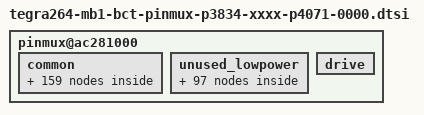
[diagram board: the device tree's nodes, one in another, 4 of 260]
/*This dtsi file was generated by T264_Pinmux_Config_CVM_Jedha_P4070.xlsm Revision: 9 */
/*
 * SPDX-FileCopyrightText: Copyright (c) 2024-2025 NVIDIA CORPORATION & AFFILIATES. All rights reserved.
 * SPDX-License-Identifier: BSD-3-Clause
 *
 * Redistribution and use in source and binary forms, with or without
 * modification, are permitted provided that the following conditions are met:
 *
 * 1. Redistributions of source code must retain the above copyright notice, this
 * list of conditions and the following disclaimer.
 *
 * 2. Redistributions in binary form must reproduce the above copyright notice,
 * this list of conditions and the following disclaimer in the documentation
 * and/or other materials provided with the distribution.
 * 
 * 3. Neither the name of the copyright holder nor the names of its
 * contributors may be used to endorse or promote products derived from
 * this software without specific prior written permission.
 *
 * THIS SOFTWARE IS PROVIDED BY THE COPYRIGHT HOLDERS AND CONTRIBUTORS 'AS IS'
 * AND ANY EXPRESS OR IMPLIED WARRANTIES, INCLUDING, BUT NOT LIMITED TO, THE
 * IMPLIED WARRANTIES OF MERCHANTABILITY AND FITNESS FOR A PARTICULAR PURPOSE ARE
 * DISCLAIMED. IN NO EVENT SHALL THE COPYRIGHT HOLDER OR CONTRIBUTORS BE LIABLE
 * FOR ANY DIRECT, INDIRECT, INCIDENTAL, SPECIAL, EXEMPLARY, OR CONSEQUENTIAL
 * DAMAGES (INCLUDING, BUT NOT LIMITED TO, PROCUREMENT OF SUBSTITUTE GOODS OR
 * SERVICES; LOSS OF USE, DATA, OR PROFITS; OR BUSINESS INTERRUPTION) HOWEVER
 * CAUSED AND ON ANY THEORY OF LIABILITY, WHETHER IN CONTRACT, STRICT LIABILITY,
 * OR TORT (INCLUDING NEGLIGENCE OR OTHERWISE) ARISING IN ANY WAY OUT OF THE USE
 * OF THIS SOFTWARE, EVEN IF ADVISED OF THE POSSIBILITY OF SUCH DAMAGE.
 */


#include "t264-pinctrl-tegra.h"

#include "./tegra264-mb1-bct-gpio-p3834-xxxx-p4071-0000.dtsi"

pinmux@ac281000 {
		common {
			/* SFIO Pin Configuration */
			shutdown_n {
				nvidia,pins = "shutdown_n";
				nvidia,function = "shutdown_n";
				nvidia,pull = <TEGRA_PIN_PULL_NONE>;
				nvidia,tristate = <TEGRA_PIN_DISABLE>;
				nvidia,enable-input = <TEGRA_PIN_DISABLE>;
				nvidia,drv-type = <TEGRA_PIN_1X_DRIVER>;
				nvidia,e-io-od = <TEGRA_PIN_ENABLE>;
				nvidia,e-lpbk = <TEGRA_PIN_DISABLE>;
			};

			batt_oc_paa3 {
				nvidia,pins = "batt_oc_paa3";
				nvidia,function = "soc_therm_oc2";
				nvidia,pull = <TEGRA_PIN_PULL_UP>;
				nvidia,tristate = <TEGRA_PIN_ENABLE>;
				nvidia,enable-input = <TEGRA_PIN_ENABLE>;
				nvidia,drv-type = <TEGRA_PIN_1X_DRIVER>;
				nvidia,e-io-od = <TEGRA_PIN_DISABLE>;
				nvidia,e-lpbk = <TEGRA_PIN_DISABLE>;
			};

			hdmi_cec_paa6 {
				nvidia,pins = "hdmi_cec_paa6";
				nvidia,function = "hdmi_cec";
				nvidia,pull = <TEGRA_PIN_PULL_NONE>;
				nvidia,tristate = <TEGRA_PIN_DISABLE>;
				nvidia,enable-input = <TEGRA_PIN_ENABLE>;
				nvidia,drv-type = <TEGRA_PIN_1X_DRIVER>;
				nvidia,e-io-od = <TEGRA_PIN_ENABLE>;
				nvidia,e-lpbk = <TEGRA_PIN_DISABLE>;
			};

			gen2_i2c_scl_pcc0 {
				nvidia,pins = "gen2_i2c_scl_pcc0";
				nvidia,function = "i2c2_clk";
				nvidia,pull = <TEGRA_PIN_PULL_NONE>;
				nvidia,tristate = <TEGRA_PIN_DISABLE>;
				nvidia,enable-input = <TEGRA_PIN_ENABLE>;
				nvidia,drv-type = <TEGRA_PIN_1X_DRIVER>;
				nvidia,e-io-od = <TEGRA_PIN_ENABLE>;
				nvidia,e-lpbk = <TEGRA_PIN_DISABLE>;
			};

			gen2_i2c_sda_pcc1 {
				nvidia,pins = "gen2_i2c_sda_pcc1";
				nvidia,function = "i2c2_dat";
				nvidia,pull = <TEGRA_PIN_PULL_NONE>;
				nvidia,tristate = <TEGRA_PIN_DISABLE>;
				nvidia,enable-input = <TEGRA_PIN_ENABLE>;
				nvidia,drv-type = <TEGRA_PIN_1X_DRIVER>;
				nvidia,e-io-od = <TEGRA_PIN_ENABLE>;
				nvidia,e-lpbk = <TEGRA_PIN_DISABLE>;
			};

			gen3_i2c_scl_pcc2 {
				nvidia,pins = "gen3_i2c_scl_pcc2";
				nvidia,function = "i2c3_clk";
				nvidia,pull = <TEGRA_PIN_PULL_NONE>;
				nvidia,tristate = <TEGRA_PIN_DISABLE>;
				nvidia,enable-input = <TEGRA_PIN_ENABLE>;
				nvidia,drv-type = <TEGRA_PIN_1X_DRIVER>;
				nvidia,e-io-od = <TEGRA_PIN_ENABLE>;
				nvidia,e-lpbk = <TEGRA_PIN_DISABLE>;
			};

			gen3_i2c_sda_pcc3 {
				nvidia,pins = "gen3_i2c_sda_pcc3";
				nvidia,function = "i2c3_dat";
				nvidia,pull = <TEGRA_PIN_PULL_NONE>;
				nvidia,tristate = <TEGRA_PIN_DISABLE>;
				nvidia,enable-input = <TEGRA_PIN_ENABLE>;
				nvidia,drv-type = <TEGRA_PIN_1X_DRIVER>;
				nvidia,e-io-od = <TEGRA_PIN_ENABLE>;
				nvidia,e-lpbk = <TEGRA_PIN_DISABLE>;
			};

			gp_pwm4_pcc4 {
				nvidia,pins = "gp_pwm4_pcc4";
				nvidia,function = "gp_pwm4";
				nvidia,pull = <TEGRA_PIN_PULL_NONE>;
				nvidia,tristate = <TEGRA_PIN_DISABLE>;
				nvidia,enable-input = <TEGRA_PIN_DISABLE>;
				nvidia,drv-type = <TEGRA_PIN_1X_DRIVER>;
				nvidia,e-io-od = <TEGRA_PIN_DISABLE>;
				nvidia,e-lpbk = <TEGRA_PIN_DISABLE>;
			};

			uart0_tx_pcc5 {
				nvidia,pins = "uart0_tx_pcc5";
				nvidia,function = "uarta_txd";
				nvidia,pull = <TEGRA_PIN_PULL_NONE>;
				nvidia,tristate = <TEGRA_PIN_DISABLE>;
				nvidia,enable-input = <TEGRA_PIN_DISABLE>;
				nvidia,drv-type = <TEGRA_PIN_1X_DRIVER>;
				nvidia,e-io-od = <TEGRA_PIN_DISABLE>;
				nvidia,e-lpbk = <TEGRA_PIN_DISABLE>;
			};

			uart0_rx_pcc6 {
				nvidia,pins = "uart0_rx_pcc6";
				nvidia,function = "uarta_rxd";
				nvidia,pull = <TEGRA_PIN_PULL_NONE>;
				nvidia,tristate = <TEGRA_PIN_ENABLE>;
				nvidia,enable-input = <TEGRA_PIN_ENABLE>;
				nvidia,drv-type = <TEGRA_PIN_1X_DRIVER>;
				nvidia,e-io-od = <TEGRA_PIN_DISABLE>;
				nvidia,e-lpbk = <TEGRA_PIN_DISABLE>;
			};

			soc_gpio23_pdd5 {
				nvidia,pins = "soc_gpio23_pdd5";
				nvidia,function = "tsc_edge_out2";
				nvidia,pull = <TEGRA_PIN_PULL_NONE>;
				nvidia,tristate = <TEGRA_PIN_DISABLE>;
				nvidia,enable-input = <TEGRA_PIN_DISABLE>;
				nvidia,drv-type = <TEGRA_PIN_1X_DRIVER>;
				nvidia,e-io-od = <TEGRA_PIN_DISABLE>;
				nvidia,e-lpbk = <TEGRA_PIN_DISABLE>;
			};

			soc_gpio25_pdd7 {
				nvidia,pins = "soc_gpio25_pdd7";
				nvidia,function = "tsc_edge_out0";
				nvidia,pull = <TEGRA_PIN_PULL_NONE>;
				nvidia,tristate = <TEGRA_PIN_DISABLE>;
				nvidia,enable-input = <TEGRA_PIN_DISABLE>;
				nvidia,drv-type = <TEGRA_PIN_1X_DRIVER>;
				nvidia,e-io-od = <TEGRA_PIN_DISABLE>;
				nvidia,e-lpbk = <TEGRA_PIN_DISABLE>;
			};

			soc_gpio26_pee0 {
				nvidia,pins = "soc_gpio26_pee0";
				nvidia,function = "tsc_edge_out1";
				nvidia,pull = <TEGRA_PIN_PULL_NONE>;
				nvidia,tristate = <TEGRA_PIN_DISABLE>;
				nvidia,enable-input = <TEGRA_PIN_DISABLE>;
				nvidia,drv-type = <TEGRA_PIN_1X_DRIVER>;
				nvidia,e-io-od = <TEGRA_PIN_DISABLE>;
				nvidia,e-lpbk = <TEGRA_PIN_DISABLE>;
			};

			soc_gpio28_pee2 {
				nvidia,pins = "soc_gpio28_pee2";
				nvidia,function = "l0l1_rst_out_n";
				nvidia,pull = <TEGRA_PIN_PULL_UP>;
				nvidia,tristate = <TEGRA_PIN_DISABLE>;
				nvidia,enable-input = <TEGRA_PIN_DISABLE>;
				nvidia,drv-type = <TEGRA_PIN_1X_DRIVER>;
				nvidia,e-io-od = <TEGRA_PIN_DISABLE>;
				nvidia,e-lpbk = <TEGRA_PIN_DISABLE>;
			};

			soc_gpio29_pee3 {
				nvidia,pins = "soc_gpio29_pee3";
				nvidia,function = "l2_rst_out_n";
				nvidia,pull = <TEGRA_PIN_PULL_UP>;
				nvidia,tristate = <TEGRA_PIN_DISABLE>;
				nvidia,enable-input = <TEGRA_PIN_DISABLE>;
				nvidia,drv-type = <TEGRA_PIN_1X_DRIVER>;
				nvidia,e-io-od = <TEGRA_PIN_DISABLE>;
				nvidia,e-lpbk = <TEGRA_PIN_DISABLE>;
			};

			qspi2_sck {
				nvidia,pins = "qspi2_sck";
				nvidia,function = "qspi2_sck";
				nvidia,pull = <TEGRA_PIN_PULL_DOWN>;
				nvidia,tristate = <TEGRA_PIN_DISABLE>;
				nvidia,enable-input = <TEGRA_PIN_ENABLE>;
				nvidia,drv-type = <TEGRA_PIN_2X_DRIVER>;
				nvidia,e-io-od = <TEGRA_PIN_DISABLE>;
				nvidia,e-lpbk = <TEGRA_PIN_ENABLE>;
			};

			qspi2_cs0 {
				nvidia,pins = "qspi2_cs0";
				nvidia,function = "qspi2_cs0";
				nvidia,pull = <TEGRA_PIN_PULL_UP>;
				nvidia,tristate = <TEGRA_PIN_DISABLE>;
				nvidia,enable-input = <TEGRA_PIN_DISABLE>;
				nvidia,drv-type = <TEGRA_PIN_2X_DRIVER>;
				nvidia,e-io-od = <TEGRA_PIN_DISABLE>;
				nvidia,e-lpbk = <TEGRA_PIN_DISABLE>;
			};

			qspi2_d0 {
				nvidia,pins = "qspi2_d0";
				nvidia,function = "qspi2_io0";
				nvidia,pull = <TEGRA_PIN_PULL_UP>;
				nvidia,tristate = <TEGRA_PIN_DISABLE>;
				nvidia,enable-input = <TEGRA_PIN_ENABLE>;
				nvidia,drv-type = <TEGRA_PIN_2X_DRIVER>;
				nvidia,e-io-od = <TEGRA_PIN_DISABLE>;
				nvidia,e-lpbk = <TEGRA_PIN_DISABLE>;
			};

			qspi2_d1 {
				nvidia,pins = "qspi2_d1";
				nvidia,function = "qspi2_io1";
				nvidia,pull = <TEGRA_PIN_PULL_UP>;
				nvidia,tristate = <TEGRA_PIN_DISABLE>;
				nvidia,enable-input = <TEGRA_PIN_ENABLE>;
				nvidia,drv-type = <TEGRA_PIN_2X_DRIVER>;
				nvidia,e-io-od = <TEGRA_PIN_DISABLE>;
				nvidia,e-lpbk = <TEGRA_PIN_DISABLE>;
			};

			pwm1_pa0 {
				nvidia,pins = "pwm1_pa0";
				nvidia,function = "gp_pwm1";
				nvidia,pull = <TEGRA_PIN_PULL_NONE>;
				nvidia,tristate = <TEGRA_PIN_ENABLE>;
				nvidia,enable-input = <TEGRA_PIN_DISABLE>;
				nvidia,drv-type = <TEGRA_PIN_1X_DRIVER>;
				nvidia,e-io-od = <TEGRA_PIN_DISABLE>;
				nvidia,e-lpbk = <TEGRA_PIN_DISABLE>;
			};

			pwm6_pa1 {
				nvidia,pins = "pwm6_pa1";
				nvidia,function = "gp_pwm6";
				nvidia,pull = <TEGRA_PIN_PULL_NONE>;
				nvidia,tristate = <TEGRA_PIN_ENABLE>;
				nvidia,enable-input = <TEGRA_PIN_DISABLE>;
				nvidia,drv-type = <TEGRA_PIN_1X_DRIVER>;
				nvidia,e-io-od = <TEGRA_PIN_DISABLE>;
				nvidia,e-lpbk = <TEGRA_PIN_DISABLE>;
			};

			pwm7_pa2 {
				nvidia,pins = "pwm7_pa2";
				nvidia,function = "gp_pwm7";
				nvidia,pull = <TEGRA_PIN_PULL_NONE>;
				nvidia,tristate = <TEGRA_PIN_ENABLE>;
				nvidia,enable-input = <TEGRA_PIN_DISABLE>;
				nvidia,drv-type = <TEGRA_PIN_1X_DRIVER>;
				nvidia,e-io-od = <TEGRA_PIN_DISABLE>;
				nvidia,e-lpbk = <TEGRA_PIN_DISABLE>;
			};

			pwm8_pa3 {
				nvidia,pins = "pwm8_pa3";
				nvidia,function = "gp_pwm8";
				nvidia,pull = <TEGRA_PIN_PULL_NONE>;
				nvidia,tristate = <TEGRA_PIN_ENABLE>;
				nvidia,enable-input = <TEGRA_PIN_DISABLE>;
				nvidia,drv-type = <TEGRA_PIN_1X_DRIVER>;
				nvidia,e-io-od = <TEGRA_PIN_DISABLE>;
				nvidia,e-lpbk = <TEGRA_PIN_DISABLE>;
			};

			ufs0_ref_clk_pa4 {
				nvidia,pins = "ufs0_ref_clk_pa4";
				nvidia,function = "ufs0";
				nvidia,pull = <TEGRA_PIN_PULL_NONE>;
				nvidia,tristate = <TEGRA_PIN_DISABLE>;
				nvidia,enable-input = <TEGRA_PIN_DISABLE>;
				nvidia,drv-type = <TEGRA_PIN_2X_DRIVER>;
				nvidia,e-io-od = <TEGRA_PIN_DISABLE>;
				nvidia,e-lpbk = <TEGRA_PIN_DISABLE>;
			};

			ufs0_rst_n_pa5 {
				nvidia,pins = "ufs0_rst_n_pa5";
				nvidia,function = "ufs0";
				nvidia,pull = <TEGRA_PIN_PULL_NONE>;
				nvidia,tristate = <TEGRA_PIN_DISABLE>;
				nvidia,enable-input = <TEGRA_PIN_DISABLE>;
				nvidia,drv-type = <TEGRA_PIN_2X_DRIVER>;
				nvidia,e-io-od = <TEGRA_PIN_DISABLE>;
				nvidia,e-lpbk = <TEGRA_PIN_DISABLE>;
			};

			pex_l1_clkreq_n_pb0 {
				nvidia,pins = "pex_l1_clkreq_n_pb0";
				nvidia,function = "pe1_clkreq_l";
				nvidia,pull = <TEGRA_PIN_PULL_NONE>;
				nvidia,tristate = <TEGRA_PIN_DISABLE>;
				nvidia,enable-input = <TEGRA_PIN_ENABLE>;
				nvidia,drv-type = <TEGRA_PIN_1X_DRIVER>;
				nvidia,e-io-od = <TEGRA_PIN_ENABLE>;
				nvidia,e-lpbk = <TEGRA_PIN_DISABLE>;
			};

			pex_l1_rst_n_pb1 {
				nvidia,pins = "pex_l1_rst_n_pb1";
				nvidia,function = "pe1_rst_l";
				nvidia,pull = <TEGRA_PIN_PULL_NONE>;
				nvidia,tristate = <TEGRA_PIN_DISABLE>;
				nvidia,enable-input = <TEGRA_PIN_DISABLE>;
				nvidia,drv-type = <TEGRA_PIN_1X_DRIVER>;
				nvidia,e-io-od = <TEGRA_PIN_ENABLE>;
				nvidia,e-lpbk = <TEGRA_PIN_DISABLE>;
			};

			pex_l2_clkreq_n_pb2 {
				nvidia,pins = "pex_l2_clkreq_n_pb2";
				nvidia,function = "pe2_clkreq_l";
				nvidia,pull = <TEGRA_PIN_PULL_NONE>;
				nvidia,tristate = <TEGRA_PIN_DISABLE>;
				nvidia,enable-input = <TEGRA_PIN_ENABLE>;
				nvidia,drv-type = <TEGRA_PIN_1X_DRIVER>;
				nvidia,e-io-od = <TEGRA_PIN_ENABLE>;
				nvidia,e-lpbk = <TEGRA_PIN_DISABLE>;
			};

			pex_l2_rst_n_pb3 {
				nvidia,pins = "pex_l2_rst_n_pb3";
				nvidia,function = "pe2_rst_l";
				nvidia,pull = <TEGRA_PIN_PULL_NONE>;
				nvidia,tristate = <TEGRA_PIN_DISABLE>;
				nvidia,enable-input = <TEGRA_PIN_DISABLE>;
				nvidia,drv-type = <TEGRA_PIN_1X_DRIVER>;
				nvidia,e-io-od = <TEGRA_PIN_ENABLE>;
				nvidia,e-lpbk = <TEGRA_PIN_DISABLE>;
			};

			pex_l3_clkreq_n_pb4 {
				nvidia,pins = "pex_l3_clkreq_n_pb4";
				nvidia,function = "pe3_clkreq_l";
				nvidia,pull = <TEGRA_PIN_PULL_NONE>;
				nvidia,tristate = <TEGRA_PIN_DISABLE>;
				nvidia,enable-input = <TEGRA_PIN_ENABLE>;
				nvidia,drv-type = <TEGRA_PIN_1X_DRIVER>;
				nvidia,e-io-od = <TEGRA_PIN_ENABLE>;
				nvidia,e-lpbk = <TEGRA_PIN_DISABLE>;
			};

			pex_l3_rst_n_pb5 {
				nvidia,pins = "pex_l3_rst_n_pb5";
				nvidia,function = "pe3_rst_l";
				nvidia,pull = <TEGRA_PIN_PULL_NONE>;
				nvidia,tristate = <TEGRA_PIN_DISABLE>;
				nvidia,enable-input = <TEGRA_PIN_DISABLE>;
				nvidia,drv-type = <TEGRA_PIN_1X_DRIVER>;
				nvidia,e-io-od = <TEGRA_PIN_ENABLE>;
				nvidia,e-lpbk = <TEGRA_PIN_DISABLE>;
			};

			pex_l5_clkreq_n_pd2 {
				nvidia,pins = "pex_l5_clkreq_n_pd2";
				nvidia,function = "pe5_clkreq_l";
				nvidia,pull = <TEGRA_PIN_PULL_NONE>;
				nvidia,tristate = <TEGRA_PIN_DISABLE>;
				nvidia,enable-input = <TEGRA_PIN_ENABLE>;
				nvidia,drv-type = <TEGRA_PIN_1X_DRIVER>;
				nvidia,e-io-od = <TEGRA_PIN_DISABLE>;
				nvidia,e-lpbk = <TEGRA_PIN_DISABLE>;
			};

			pex_l5_rst_n_pd3 {
				nvidia,pins = "pex_l5_rst_n_pd3";
				nvidia,function = "pe5_rst_l";
				nvidia,pull = <TEGRA_PIN_PULL_NONE>;
				nvidia,tristate = <TEGRA_PIN_DISABLE>;
				nvidia,enable-input = <TEGRA_PIN_DISABLE>;
				nvidia,drv-type = <TEGRA_PIN_1X_DRIVER>;
				nvidia,e-io-od = <TEGRA_PIN_DISABLE>;
				nvidia,e-lpbk = <TEGRA_PIN_DISABLE>;
			};

			can0_dout_pab0 {
				nvidia,pins = "can0_dout_pab0";
				nvidia,function = "can0_dout";
				nvidia,pull = <TEGRA_PIN_PULL_NONE>;
				nvidia,tristate = <TEGRA_PIN_DISABLE>;
				nvidia,enable-input = <TEGRA_PIN_DISABLE>;
				nvidia,drv-type = <TEGRA_PIN_DEFAULT_DRIVE_1X>;
				nvidia,e-lpbk = <TEGRA_PIN_DISABLE>;
			};

			can0_din_pab1 {
				nvidia,pins = "can0_din_pab1";
				nvidia,function = "can0_din";
				nvidia,pull = <TEGRA_PIN_PULL_NONE>;
				nvidia,tristate = <TEGRA_PIN_ENABLE>;
				nvidia,enable-input = <TEGRA_PIN_ENABLE>;
				nvidia,drv-type = <TEGRA_PIN_DEFAULT_DRIVE_1X>;
				nvidia,e-lpbk = <TEGRA_PIN_DISABLE>;
			};

			can1_dout_pac0 {
				nvidia,pins = "can1_dout_pac0";
				nvidia,function = "can1_dout";
				nvidia,pull = <TEGRA_PIN_PULL_NONE>;
				nvidia,tristate = <TEGRA_PIN_DISABLE>;
				nvidia,enable-input = <TEGRA_PIN_DISABLE>;
				nvidia,drv-type = <TEGRA_PIN_DEFAULT_DRIVE_1X>;
				nvidia,e-lpbk = <TEGRA_PIN_DISABLE>;
			};

			can1_din_pac1 {
				nvidia,pins = "can1_din_pac1";
				nvidia,function = "can1_din";
				nvidia,pull = <TEGRA_PIN_PULL_NONE>;
				nvidia,tristate = <TEGRA_PIN_ENABLE>;
				nvidia,enable-input = <TEGRA_PIN_ENABLE>;
				nvidia,drv-type = <TEGRA_PIN_DEFAULT_DRIVE_1X>;
				nvidia,e-lpbk = <TEGRA_PIN_DISABLE>;
			};

			can2_dout_pad0 {
				nvidia,pins = "can2_dout_pad0";
				nvidia,function = "can2_dout";
				nvidia,pull = <TEGRA_PIN_PULL_NONE>;
				nvidia,tristate = <TEGRA_PIN_DISABLE>;
				nvidia,enable-input = <TEGRA_PIN_DISABLE>;
				nvidia,drv-type = <TEGRA_PIN_DEFAULT_DRIVE_1X>;
				nvidia,e-lpbk = <TEGRA_PIN_DISABLE>;
			};

			can2_din_pad1 {
				nvidia,pins = "can2_din_pad1";
				nvidia,function = "can2_din";
				nvidia,pull = <TEGRA_PIN_PULL_NONE>;
				nvidia,tristate = <TEGRA_PIN_ENABLE>;
				nvidia,enable-input = <TEGRA_PIN_ENABLE>;
				nvidia,drv-type = <TEGRA_PIN_DEFAULT_DRIVE_1X>;
				nvidia,e-lpbk = <TEGRA_PIN_DISABLE>;
			};

			can3_dout_pae0 {
				nvidia,pins = "can3_dout_pae0";
				nvidia,function = "can3_dout";
				nvidia,pull = <TEGRA_PIN_PULL_NONE>;
				nvidia,tristate = <TEGRA_PIN_DISABLE>;
				nvidia,enable-input = <TEGRA_PIN_DISABLE>;
				nvidia,drv-type = <TEGRA_PIN_DEFAULT_DRIVE_1X>;
				nvidia,e-lpbk = <TEGRA_PIN_DISABLE>;
			};

			can3_din_pae1 {
				nvidia,pins = "can3_din_pae1";
				nvidia,function = "can3_din";
				nvidia,pull = <TEGRA_PIN_PULL_NONE>;
				nvidia,tristate = <TEGRA_PIN_ENABLE>;
				nvidia,enable-input = <TEGRA_PIN_ENABLE>;
				nvidia,drv-type = <TEGRA_PIN_DEFAULT_DRIVE_1X>;
				nvidia,e-lpbk = <TEGRA_PIN_DISABLE>;
			};

			dp_aux_ch0_hpd_pf3 {
				nvidia,pins = "dp_aux_ch0_hpd_pf3";
				nvidia,function = "dp_aux_ch0_hpd";
				nvidia,pull = <TEGRA_PIN_PULL_NONE>;
				nvidia,tristate = <TEGRA_PIN_ENABLE>;
				nvidia,enable-input = <TEGRA_PIN_ENABLE>;
				nvidia,drv-type = <TEGRA_PIN_1X_DRIVER>;
				nvidia,e-io-od = <TEGRA_PIN_DISABLE>;
				nvidia,e-lpbk = <TEGRA_PIN_DISABLE>;
			};

			dp_aux_ch2_hpd_pf5 {
				nvidia,pins = "dp_aux_ch2_hpd_pf5";
				nvidia,function = "dp_aux_ch2_hpd";
				nvidia,pull = <TEGRA_PIN_PULL_NONE>;
				nvidia,tristate = <TEGRA_PIN_ENABLE>;
				nvidia,enable-input = <TEGRA_PIN_ENABLE>;
				nvidia,drv-type = <TEGRA_PIN_1X_DRIVER>;
				nvidia,e-io-od = <TEGRA_PIN_DISABLE>;
				nvidia,e-lpbk = <TEGRA_PIN_DISABLE>;
			};

			dp_aux_ch3_hpd_pf6 {
				nvidia,pins = "dp_aux_ch3_hpd_pf6";
				nvidia,function = "dp_aux_ch3_hpd";
				nvidia,pull = <TEGRA_PIN_PULL_NONE>;
				nvidia,tristate = <TEGRA_PIN_ENABLE>;
				nvidia,enable-input = <TEGRA_PIN_ENABLE>;
				nvidia,drv-type = <TEGRA_PIN_1X_DRIVER>;
				nvidia,e-io-od = <TEGRA_PIN_DISABLE>;
				nvidia,e-lpbk = <TEGRA_PIN_DISABLE>;
			};

			pwm2_pf7 {
				nvidia,pins = "pwm2_pf7";
				nvidia,function = "gp_pwm2";
				nvidia,pull = <TEGRA_PIN_PULL_NONE>;
				nvidia,tristate = <TEGRA_PIN_DISABLE>;
				nvidia,enable-input = <TEGRA_PIN_DISABLE>;
				nvidia,drv-type = <TEGRA_PIN_1X_DRIVER>;
				nvidia,e-io-od = <TEGRA_PIN_DISABLE>;
				nvidia,e-lpbk = <TEGRA_PIN_DISABLE>;
			};

			pwm3_pg0 {
				nvidia,pins = "pwm3_pg0";
				nvidia,function = "gp_pwm3";
				nvidia,pull = <TEGRA_PIN_PULL_NONE>;
				nvidia,tristate = <TEGRA_PIN_DISABLE>;
				nvidia,enable-input = <TEGRA_PIN_DISABLE>;
				nvidia,drv-type = <TEGRA_PIN_1X_DRIVER>;
				nvidia,e-io-od = <TEGRA_PIN_DISABLE>;
				nvidia,e-lpbk = <TEGRA_PIN_DISABLE>;
			};

			gen7_i2c_scl_pg1 {
				nvidia,pins = "gen7_i2c_scl_pg1";
				nvidia,function = "i2c7_clk";
				nvidia,pull = <TEGRA_PIN_PULL_NONE>;
				nvidia,tristate = <TEGRA_PIN_DISABLE>;
				nvidia,enable-input = <TEGRA_PIN_ENABLE>;
				nvidia,drv-type = <TEGRA_PIN_1X_DRIVER>;
				nvidia,e-io-od = <TEGRA_PIN_ENABLE>;
				nvidia,e-lpbk = <TEGRA_PIN_DISABLE>;
			};

			gen7_i2c_sda_pg2 {
				nvidia,pins = "gen7_i2c_sda_pg2";
				nvidia,function = "i2c7_dat";
				nvidia,pull = <TEGRA_PIN_PULL_NONE>;
				nvidia,tristate = <TEGRA_PIN_DISABLE>;
				nvidia,enable-input = <TEGRA_PIN_ENABLE>;
				nvidia,drv-type = <TEGRA_PIN_1X_DRIVER>;
				nvidia,e-io-od = <TEGRA_PIN_ENABLE>;
				nvidia,e-lpbk = <TEGRA_PIN_DISABLE>;
			};

			gen9_i2c_scl_pg3 {
				nvidia,pins = "gen9_i2c_scl_pg3";
				nvidia,function = "i2c9_clk";
				nvidia,pull = <TEGRA_PIN_PULL_NONE>;
				nvidia,tristate = <TEGRA_PIN_DISABLE>;
				nvidia,enable-input = <TEGRA_PIN_ENABLE>;
				nvidia,drv-type = <TEGRA_PIN_1X_DRIVER>;
				nvidia,e-io-od = <TEGRA_PIN_ENABLE>;
				nvidia,e-lpbk = <TEGRA_PIN_DISABLE>;
			};

			gen9_i2c_sda_pg4 {
				nvidia,pins = "gen9_i2c_sda_pg4";
				nvidia,function = "i2c9_dat";
				nvidia,pull = <TEGRA_PIN_PULL_NONE>;
				nvidia,tristate = <TEGRA_PIN_DISABLE>;
				nvidia,enable-input = <TEGRA_PIN_ENABLE>;
				nvidia,drv-type = <TEGRA_PIN_1X_DRIVER>;
				nvidia,e-io-od = <TEGRA_PIN_ENABLE>;
				nvidia,e-lpbk = <TEGRA_PIN_DISABLE>;
			};

			dp_aux_ch0_p {
				nvidia,pins = "dp_aux_ch0_p";
				nvidia,function = "dp_aux_ch0_p";
				nvidia,pull = <TEGRA_PIN_PULL_NONE>;
				nvidia,tristate = <TEGRA_PIN_DISABLE>;
				nvidia,enable-input = <TEGRA_PIN_ENABLE>;
				nvidia,drv-type = <TEGRA_PIN_1X_DRIVER>;
				nvidia,e-io-od = <TEGRA_PIN_DISABLE>;
				nvidia,e-lpbk = <TEGRA_PIN_DISABLE>;
			};

			dp_aux_ch0_n {
				nvidia,pins = "dp_aux_ch0_n";
				nvidia,function = "dp_aux_ch0_n";
				nvidia,pull = <TEGRA_PIN_PULL_NONE>;
				nvidia,tristate = <TEGRA_PIN_DISABLE>;
				nvidia,enable-input = <TEGRA_PIN_ENABLE>;
				nvidia,drv-type = <TEGRA_PIN_1X_DRIVER>;
				nvidia,e-io-od = <TEGRA_PIN_DISABLE>;
				nvidia,e-lpbk = <TEGRA_PIN_DISABLE>;
			};

			dp_aux_ch1_p {
				nvidia,pins = "dp_aux_ch1_p";
				nvidia,function = "i2c10_clk";
				nvidia,pull = <TEGRA_PIN_PULL_NONE>;
				nvidia,tristate = <TEGRA_PIN_DISABLE>;
				nvidia,enable-input = <TEGRA_PIN_ENABLE>;
				nvidia,drv-type = <TEGRA_PIN_1X_DRIVER>;
				nvidia,e-io-od = <TEGRA_PIN_ENABLE>;
				nvidia,e-lpbk = <TEGRA_PIN_DISABLE>;
			};

			dp_aux_ch1_n {
				nvidia,pins = "dp_aux_ch1_n";
				nvidia,function = "i2c10_dat";
				nvidia,pull = <TEGRA_PIN_PULL_NONE>;
				nvidia,tristate = <TEGRA_PIN_DISABLE>;
				nvidia,enable-input = <TEGRA_PIN_ENABLE>;
				nvidia,drv-type = <TEGRA_PIN_1X_DRIVER>;
				nvidia,e-io-od = <TEGRA_PIN_ENABLE>;
				nvidia,e-lpbk = <TEGRA_PIN_DISABLE>;
			};

			dp_aux_ch2_p {
				nvidia,pins = "dp_aux_ch2_p";
				nvidia,function = "dp_aux_ch2_p";
				nvidia,pull = <TEGRA_PIN_PULL_NONE>;
				nvidia,tristate = <TEGRA_PIN_DISABLE>;
				nvidia,enable-input = <TEGRA_PIN_ENABLE>;
				nvidia,drv-type = <TEGRA_PIN_1X_DRIVER>;
				nvidia,e-io-od = <TEGRA_PIN_DISABLE>;
				nvidia,e-lpbk = <TEGRA_PIN_DISABLE>;
			};

			dp_aux_ch2_n {
				nvidia,pins = "dp_aux_ch2_n";
				nvidia,function = "dp_aux_ch2_n";
				nvidia,pull = <TEGRA_PIN_PULL_NONE>;
				nvidia,tristate = <TEGRA_PIN_DISABLE>;
				nvidia,enable-input = <TEGRA_PIN_ENABLE>;
				nvidia,drv-type = <TEGRA_PIN_1X_DRIVER>;
				nvidia,e-io-od = <TEGRA_PIN_DISABLE>;
				nvidia,e-lpbk = <TEGRA_PIN_DISABLE>;
			};

			dp_aux_ch3_p {
				nvidia,pins = "dp_aux_ch3_p";
				nvidia,function = "dp_aux_ch3_p";
				nvidia,pull = <TEGRA_PIN_PULL_NONE>;
				nvidia,tristate = <TEGRA_PIN_DISABLE>;
				nvidia,enable-input = <TEGRA_PIN_ENABLE>;
				nvidia,drv-type = <TEGRA_PIN_1X_DRIVER>;
				nvidia,e-io-od = <TEGRA_PIN_DISABLE>;
				nvidia,e-lpbk = <TEGRA_PIN_DISABLE>;
			};

			dp_aux_ch3_n {
				nvidia,pins = "dp_aux_ch3_n";
				nvidia,function = "dp_aux_ch3_n";
				nvidia,pull = <TEGRA_PIN_PULL_NONE>;
				nvidia,tristate = <TEGRA_PIN_DISABLE>;
				nvidia,enable-input = <TEGRA_PIN_ENABLE>;
				nvidia,drv-type = <TEGRA_PIN_1X_DRIVER>;
				nvidia,e-io-od = <TEGRA_PIN_DISABLE>;
				nvidia,e-lpbk = <TEGRA_PIN_DISABLE>;
			};

			uart10_tx_ph2 {
				nvidia,pins = "uart10_tx_ph2";
				nvidia,function = "uartk_txd";
				nvidia,pull = <TEGRA_PIN_PULL_NONE>;
				nvidia,tristate = <TEGRA_PIN_DISABLE>;
				nvidia,enable-input = <TEGRA_PIN_DISABLE>;
				nvidia,drv-type = <TEGRA_PIN_1X_DRIVER>;
				nvidia,e-io-od = <TEGRA_PIN_DISABLE>;
				nvidia,e-lpbk = <TEGRA_PIN_DISABLE>;
			};

			uart10_rx_ph3 {
				nvidia,pins = "uart10_rx_ph3";
				nvidia,function = "uartk_rxd";
				nvidia,pull = <TEGRA_PIN_PULL_NONE>;
				nvidia,tristate = <TEGRA_PIN_ENABLE>;
				nvidia,enable-input = <TEGRA_PIN_ENABLE>;
				nvidia,drv-type = <TEGRA_PIN_1X_DRIVER>;
				nvidia,e-io-od = <TEGRA_PIN_DISABLE>;
				nvidia,e-lpbk = <TEGRA_PIN_DISABLE>;
			};

			spi3_sck_ph6 {
				nvidia,pins = "spi3_sck_ph6";
				nvidia,function = "spi3_sck";
				nvidia,pull = <TEGRA_PIN_PULL_NONE>;
				nvidia,tristate = <TEGRA_PIN_DISABLE>;
				nvidia,enable-input = <TEGRA_PIN_ENABLE>;
				nvidia,drv-type = <TEGRA_PIN_1X_DRIVER>;
				nvidia,e-io-od = <TEGRA_PIN_DISABLE>;
				nvidia,e-lpbk = <TEGRA_PIN_DISABLE>;
			};

			spi3_miso_ph7 {
				nvidia,pins = "spi3_miso_ph7";
				nvidia,function = "spi3_din";
				nvidia,pull = <TEGRA_PIN_PULL_UP>;
				nvidia,tristate = <TEGRA_PIN_DISABLE>;
				nvidia,enable-input = <TEGRA_PIN_ENABLE>;
				nvidia,drv-type = <TEGRA_PIN_1X_DRIVER>;
				nvidia,e-io-od = <TEGRA_PIN_DISABLE>;
				nvidia,e-lpbk = <TEGRA_PIN_DISABLE>;
			};

			spi3_mosi_pj0 {
				nvidia,pins = "spi3_mosi_pj0";
				nvidia,function = "spi3_dout";
				nvidia,pull = <TEGRA_PIN_PULL_NONE>;
				nvidia,tristate = <TEGRA_PIN_DISABLE>;
				nvidia,enable-input = <TEGRA_PIN_ENABLE>;
				nvidia,drv-type = <TEGRA_PIN_1X_DRIVER>;
				nvidia,e-io-od = <TEGRA_PIN_DISABLE>;
				nvidia,e-lpbk = <TEGRA_PIN_DISABLE>;
			};

			spi3_cs0_pj1 {
				nvidia,pins = "spi3_cs0_pj1";
				nvidia,function = "spi3_cs0";
				nvidia,pull = <TEGRA_PIN_PULL_NONE>;
				nvidia,tristate = <TEGRA_PIN_DISABLE>;
				nvidia,enable-input = <TEGRA_PIN_ENABLE>;
				nvidia,drv-type = <TEGRA_PIN_1X_DRIVER>;
				nvidia,e-io-od = <TEGRA_PIN_DISABLE>;
				nvidia,e-lpbk = <TEGRA_PIN_DISABLE>;
			};

			uart5_tx_pj3 {
				nvidia,pins = "uart5_tx_pj3";
				nvidia,function = "uartf_txd";
				nvidia,pull = <TEGRA_PIN_PULL_NONE>;
				nvidia,tristate = <TEGRA_PIN_DISABLE>;
				nvidia,enable-input = <TEGRA_PIN_DISABLE>;
				nvidia,drv-type = <TEGRA_PIN_1X_DRIVER>;
				nvidia,e-io-od = <TEGRA_PIN_DISABLE>;
				nvidia,e-lpbk = <TEGRA_PIN_DISABLE>;
			};

			uart5_rx_pj4 {
				nvidia,pins = "uart5_rx_pj4";
				nvidia,function = "uartf_rxd";
				nvidia,pull = <TEGRA_PIN_PULL_UP>;
				nvidia,tristate = <TEGRA_PIN_ENABLE>;
				nvidia,enable-input = <TEGRA_PIN_ENABLE>;
				nvidia,drv-type = <TEGRA_PIN_1X_DRIVER>;
				nvidia,e-io-od = <TEGRA_PIN_DISABLE>;
				nvidia,e-lpbk = <TEGRA_PIN_DISABLE>;
			};

			uart5_rts_n_pj5 {
				nvidia,pins = "uart5_rts_n_pj5";
				nvidia,function = "uartf_rts";
				nvidia,pull = <TEGRA_PIN_PULL_NONE>;
				nvidia,tristate = <TEGRA_PIN_DISABLE>;
				nvidia,enable-input = <TEGRA_PIN_DISABLE>;
				nvidia,drv-type = <TEGRA_PIN_1X_DRIVER>;
				nvidia,e-io-od = <TEGRA_PIN_DISABLE>;
				nvidia,e-lpbk = <TEGRA_PIN_DISABLE>;
			};

			uart5_cts_n_pj6 {
				nvidia,pins = "uart5_cts_n_pj6";
				nvidia,function = "uartf_cts";
				nvidia,pull = <TEGRA_PIN_PULL_UP>;
				nvidia,tristate = <TEGRA_PIN_ENABLE>;
				nvidia,enable-input = <TEGRA_PIN_ENABLE>;
				nvidia,drv-type = <TEGRA_PIN_1X_DRIVER>;
				nvidia,e-io-od = <TEGRA_PIN_DISABLE>;
				nvidia,e-lpbk = <TEGRA_PIN_DISABLE>;
			};

			extperiph1_clk_pk4 {
				nvidia,pins = "extperiph1_clk_pk4";
				nvidia,function = "extperiph1_clk";
				nvidia,pull = <TEGRA_PIN_PULL_NONE>;
				nvidia,tristate = <TEGRA_PIN_DISABLE>;
				nvidia,enable-input = <TEGRA_PIN_DISABLE>;
				nvidia,drv-type = <TEGRA_PIN_1X_DRIVER>;
				nvidia,e-io-od = <TEGRA_PIN_DISABLE>;
				nvidia,e-lpbk = <TEGRA_PIN_DISABLE>;
			};

			extperiph2_clk_pk5 {
				nvidia,pins = "extperiph2_clk_pk5";
				nvidia,function = "extperiph2_clk";
				nvidia,pull = <TEGRA_PIN_PULL_NONE>;
				nvidia,tristate = <TEGRA_PIN_DISABLE>;
				nvidia,enable-input = <TEGRA_PIN_DISABLE>;
				nvidia,drv-type = <TEGRA_PIN_1X_DRIVER>;
				nvidia,e-io-od = <TEGRA_PIN_DISABLE>;
				nvidia,e-lpbk = <TEGRA_PIN_DISABLE>;
			};

			gen12_i2c_scl_pk6 {
				nvidia,pins = "gen12_i2c_scl_pk6";
				nvidia,function = "i2c12_clk";
				nvidia,pull = <TEGRA_PIN_PULL_NONE>;
				nvidia,tristate = <TEGRA_PIN_DISABLE>;
				nvidia,enable-input = <TEGRA_PIN_ENABLE>;
				nvidia,drv-type = <TEGRA_PIN_1X_DRIVER>;
				nvidia,e-io-od = <TEGRA_PIN_ENABLE>;
				nvidia,e-lpbk = <TEGRA_PIN_DISABLE>;
			};

			gen12_i2c_sda_pk7 {
				nvidia,pins = "gen12_i2c_sda_pk7";
				nvidia,function = "i2c12_dat";
				nvidia,pull = <TEGRA_PIN_PULL_NONE>;
				nvidia,tristate = <TEGRA_PIN_DISABLE>;
				nvidia,enable-input = <TEGRA_PIN_ENABLE>;
				nvidia,drv-type = <TEGRA_PIN_1X_DRIVER>;
				nvidia,e-io-od = <TEGRA_PIN_ENABLE>;
				nvidia,e-lpbk = <TEGRA_PIN_DISABLE>;
			};

			soc_gpio124_pl0 {
				nvidia,pins = "soc_gpio124_pl0";
				nvidia,function = "soc_therm_oc3";
				nvidia,pull = <TEGRA_PIN_PULL_UP>;
				nvidia,tristate = <TEGRA_PIN_ENABLE>;
				nvidia,enable-input = <TEGRA_PIN_ENABLE>;
				nvidia,drv-type = <TEGRA_PIN_1X_DRIVER>;
				nvidia,e-io-od = <TEGRA_PIN_DISABLE>;
				nvidia,e-lpbk = <TEGRA_PIN_DISABLE>;
			};

			fan_tach0_pl2 {
				nvidia,pins = "fan_tach0_pl2";
				nvidia,function = "nv_therm_fan_tach0";
				nvidia,pull = <TEGRA_PIN_PULL_UP>;
				nvidia,tristate = <TEGRA_PIN_ENABLE>;
				nvidia,enable-input = <TEGRA_PIN_ENABLE>;
				nvidia,drv-type = <TEGRA_PIN_1X_DRIVER>;
				nvidia,e-io-od = <TEGRA_PIN_DISABLE>;
				nvidia,e-lpbk = <TEGRA_PIN_DISABLE>;
			};

			soc_gpio129_pl5 {
				nvidia,pins = "soc_gpio129_pl5";
				nvidia,function = "extperiph3_clk";
				nvidia,pull = <TEGRA_PIN_PULL_NONE>;
				nvidia,tristate = <TEGRA_PIN_DISABLE>;
				nvidia,enable-input = <TEGRA_PIN_DISABLE>;
				nvidia,drv-type = <TEGRA_PIN_1X_DRIVER>;
				nvidia,e-io-od = <TEGRA_PIN_DISABLE>;
				nvidia,e-lpbk = <TEGRA_PIN_DISABLE>;
			};

			soc_gpio130_pl6 {
				nvidia,pins = "soc_gpio130_pl6";
				nvidia,function = "extperiph4_clk";
				nvidia,pull = <TEGRA_PIN_PULL_NONE>;
				nvidia,tristate = <TEGRA_PIN_DISABLE>;
				nvidia,enable-input = <TEGRA_PIN_DISABLE>;
				nvidia,drv-type = <TEGRA_PIN_1X_DRIVER>;
				nvidia,e-io-od = <TEGRA_PIN_DISABLE>;
				nvidia,e-lpbk = <TEGRA_PIN_DISABLE>;
			};

			uart9_tx_pm2 {
				nvidia,pins = "uart9_tx_pm2";
				nvidia,function = "uartj_txd";
				nvidia,pull = <TEGRA_PIN_PULL_NONE>;
				nvidia,tristate = <TEGRA_PIN_DISABLE>;
				nvidia,enable-input = <TEGRA_PIN_DISABLE>;
				nvidia,drv-type = <TEGRA_PIN_1X_DRIVER>;
				nvidia,e-io-od = <TEGRA_PIN_DISABLE>;
				nvidia,e-lpbk = <TEGRA_PIN_DISABLE>;
			};

			uart9_rx_pm3 {
				nvidia,pins = "uart9_rx_pm3";
				nvidia,function = "uartj_rxd";
				nvidia,pull = <TEGRA_PIN_PULL_UP>;
				nvidia,tristate = <TEGRA_PIN_ENABLE>;
				nvidia,enable-input = <TEGRA_PIN_ENABLE>;
				nvidia,drv-type = <TEGRA_PIN_1X_DRIVER>;
				nvidia,e-io-od = <TEGRA_PIN_DISABLE>;
				nvidia,e-lpbk = <TEGRA_PIN_DISABLE>;
			};

			uart9_rts_n_pm4 {
				nvidia,pins = "uart9_rts_n_pm4";
				nvidia,function = "uartj_rts";
				nvidia,pull = <TEGRA_PIN_PULL_NONE>;
				nvidia,tristate = <TEGRA_PIN_DISABLE>;
				nvidia,enable-input = <TEGRA_PIN_DISABLE>;
				nvidia,drv-type = <TEGRA_PIN_1X_DRIVER>;
				nvidia,e-io-od = <TEGRA_PIN_DISABLE>;
				nvidia,e-lpbk = <TEGRA_PIN_DISABLE>;
			};

			uart9_cts_n_pm5 {
				nvidia,pins = "uart9_cts_n_pm5";
				nvidia,function = "uartj_cts";
				nvidia,pull = <TEGRA_PIN_PULL_UP>;
				nvidia,tristate = <TEGRA_PIN_ENABLE>;
				nvidia,enable-input = <TEGRA_PIN_ENABLE>;
				nvidia,drv-type = <TEGRA_PIN_1X_DRIVER>;
				nvidia,e-io-od = <TEGRA_PIN_DISABLE>;
				nvidia,e-lpbk = <TEGRA_PIN_DISABLE>;
			};

			dap4_sclk_pp6 {
				nvidia,pins = "dap4_sclk_pp6";
				nvidia,function = "i2s4_sclk";
				nvidia,pull = <TEGRA_PIN_PULL_NONE>;
				nvidia,tristate = <TEGRA_PIN_DISABLE>;
				nvidia,enable-input = <TEGRA_PIN_ENABLE>;
				nvidia,drv-type = <TEGRA_PIN_1X_DRIVER>;
				nvidia,e-io-od = <TEGRA_PIN_DISABLE>;
				nvidia,e-lpbk = <TEGRA_PIN_DISABLE>;
			};

			dap4_dout_pp7 {
				nvidia,pins = "dap4_dout_pp7";
				nvidia,function = "i2s4_sdata_out";
				nvidia,pull = <TEGRA_PIN_PULL_NONE>;
				nvidia,tristate = <TEGRA_PIN_DISABLE>;
				nvidia,enable-input = <TEGRA_PIN_DISABLE>;
				nvidia,drv-type = <TEGRA_PIN_1X_DRIVER>;
				nvidia,e-io-od = <TEGRA_PIN_DISABLE>;
				nvidia,e-lpbk = <TEGRA_PIN_DISABLE>;
			};

			dap4_din_pq0 {
				nvidia,pins = "dap4_din_pq0";
				nvidia,function = "i2s4_sdata_in";
				nvidia,pull = <TEGRA_PIN_PULL_NONE>;
				nvidia,tristate = <TEGRA_PIN_ENABLE>;
				nvidia,enable-input = <TEGRA_PIN_ENABLE>;
				nvidia,drv-type = <TEGRA_PIN_1X_DRIVER>;
				nvidia,e-io-od = <TEGRA_PIN_DISABLE>;
				nvidia,e-lpbk = <TEGRA_PIN_DISABLE>;
			};

			dap4_fs_pq1 {
				nvidia,pins = "dap4_fs_pq1";
				nvidia,function = "i2s4_lrck";
				nvidia,pull = <TEGRA_PIN_PULL_NONE>;
				nvidia,tristate = <TEGRA_PIN_DISABLE>;
				nvidia,enable-input = <TEGRA_PIN_ENABLE>;
				nvidia,drv-type = <TEGRA_PIN_1X_DRIVER>;
				nvidia,e-io-od = <TEGRA_PIN_DISABLE>;
				nvidia,e-lpbk = <TEGRA_PIN_DISABLE>;
			};

			aud_mclk_pr0 {
				nvidia,pins = "aud_mclk_pr0";
				nvidia,function = "aud_mclk";
				nvidia,pull = <TEGRA_PIN_PULL_NONE>;
				nvidia,tristate = <TEGRA_PIN_DISABLE>;
				nvidia,enable-input = <TEGRA_PIN_DISABLE>;
				nvidia,drv-type = <TEGRA_PIN_1X_DRIVER>;
				nvidia,e-io-od = <TEGRA_PIN_DISABLE>;
				nvidia,e-lpbk = <TEGRA_PIN_DISABLE>;
			};

			dap1_sclk_pr2 {
				nvidia,pins = "dap1_sclk_pr2";
				nvidia,function = "i2s1_sclk";
				nvidia,pull = <TEGRA_PIN_PULL_NONE>;
				nvidia,tristate = <TEGRA_PIN_DISABLE>;
				nvidia,enable-input = <TEGRA_PIN_ENABLE>;
				nvidia,drv-type = <TEGRA_PIN_1X_DRIVER>;
				nvidia,e-io-od = <TEGRA_PIN_DISABLE>;
				nvidia,e-lpbk = <TEGRA_PIN_DISABLE>;
			};

			dap1_out_pr3 {
				nvidia,pins = "dap1_out_pr3";
				nvidia,function = "i2s1_sdata_out";
				nvidia,pull = <TEGRA_PIN_PULL_NONE>;
				nvidia,tristate = <TEGRA_PIN_DISABLE>;
				nvidia,enable-input = <TEGRA_PIN_DISABLE>;
				nvidia,drv-type = <TEGRA_PIN_1X_DRIVER>;
				nvidia,e-io-od = <TEGRA_PIN_DISABLE>;
				nvidia,e-lpbk = <TEGRA_PIN_DISABLE>;
			};

			dap1_in_pr4 {
				nvidia,pins = "dap1_in_pr4";
				nvidia,function = "i2s1_sdata_in";
				nvidia,pull = <TEGRA_PIN_PULL_NONE>;
				nvidia,tristate = <TEGRA_PIN_ENABLE>;
				nvidia,enable-input = <TEGRA_PIN_ENABLE>;
				nvidia,drv-type = <TEGRA_PIN_1X_DRIVER>;
				nvidia,e-io-od = <TEGRA_PIN_DISABLE>;
				nvidia,e-lpbk = <TEGRA_PIN_DISABLE>;
			};

			dap1_fs_pr5 {
				nvidia,pins = "dap1_fs_pr5";
				nvidia,function = "i2s1_lrck";
				nvidia,pull = <TEGRA_PIN_PULL_NONE>;
				nvidia,tristate = <TEGRA_PIN_DISABLE>;
				nvidia,enable-input = <TEGRA_PIN_ENABLE>;
				nvidia,drv-type = <TEGRA_PIN_1X_DRIVER>;
				nvidia,e-io-od = <TEGRA_PIN_DISABLE>;
				nvidia,e-lpbk = <TEGRA_PIN_DISABLE>;
			};

			qspi0_sck_pt0 {
				nvidia,pins = "qspi0_sck_pt0";
				nvidia,function = "qspi0_sck";
				nvidia,pull = <TEGRA_PIN_PULL_DOWN>;
				nvidia,tristate = <TEGRA_PIN_DISABLE>;
				nvidia,enable-input = <TEGRA_PIN_ENABLE>;
				nvidia,drv-type = <TEGRA_PIN_2X_DRIVER>;
				nvidia,e-io-od = <TEGRA_PIN_DISABLE>;
				nvidia,e-lpbk = <TEGRA_PIN_ENABLE>;
			};

			qspi0_cs_n_pt1 {
				nvidia,pins = "qspi0_cs_n_pt1";
				nvidia,function = "qspi0_cs_n";
				nvidia,pull = <TEGRA_PIN_PULL_UP>;
				nvidia,tristate = <TEGRA_PIN_DISABLE>;
				nvidia,enable-input = <TEGRA_PIN_DISABLE>;
				nvidia,drv-type = <TEGRA_PIN_2X_DRIVER>;
				nvidia,e-io-od = <TEGRA_PIN_DISABLE>;
				nvidia,e-lpbk = <TEGRA_PIN_DISABLE>;
			};

			qspi0_io0_pt2 {
				nvidia,pins = "qspi0_io0_pt2";
				nvidia,function = "qspi0_io0";
				nvidia,pull = <TEGRA_PIN_PULL_UP>;
				nvidia,tristate = <TEGRA_PIN_DISABLE>;
				nvidia,enable-input = <TEGRA_PIN_ENABLE>;
				nvidia,drv-type = <TEGRA_PIN_2X_DRIVER>;
				nvidia,e-io-od = <TEGRA_PIN_DISABLE>;
				nvidia,e-lpbk = <TEGRA_PIN_DISABLE>;
			};

			qspi0_io1_pt3 {
				nvidia,pins = "qspi0_io1_pt3";
				nvidia,function = "qspi0_io1";
				nvidia,pull = <TEGRA_PIN_PULL_UP>;
				nvidia,tristate = <TEGRA_PIN_DISABLE>;
				nvidia,enable-input = <TEGRA_PIN_ENABLE>;
				nvidia,drv-type = <TEGRA_PIN_2X_DRIVER>;
				nvidia,e-io-od = <TEGRA_PIN_DISABLE>;
				nvidia,e-lpbk = <TEGRA_PIN_DISABLE>;
			};

			qspi0_io2_pt4 {
				nvidia,pins = "qspi0_io2_pt4";
				nvidia,function = "qspi0_io2";
				nvidia,pull = <TEGRA_PIN_PULL_UP>;
				nvidia,tristate = <TEGRA_PIN_DISABLE>;
				nvidia,enable-input = <TEGRA_PIN_ENABLE>;
				nvidia,drv-type = <TEGRA_PIN_2X_DRIVER>;
				nvidia,e-io-od = <TEGRA_PIN_DISABLE>;
				nvidia,e-lpbk = <TEGRA_PIN_DISABLE>;
			};

			qspi0_io3_pt5 {
				nvidia,pins = "qspi0_io3_pt5";
				nvidia,function = "qspi0_io3";
				nvidia,pull = <TEGRA_PIN_PULL_UP>;
				nvidia,tristate = <TEGRA_PIN_DISABLE>;
				nvidia,enable-input = <TEGRA_PIN_ENABLE>;
				nvidia,drv-type = <TEGRA_PIN_2X_DRIVER>;
				nvidia,e-io-od = <TEGRA_PIN_DISABLE>;
				nvidia,e-lpbk = <TEGRA_PIN_DISABLE>;
			};

			gen1_i2c_scl_pw2 {
				nvidia,pins = "gen1_i2c_scl_pw2";
				nvidia,function = "i2c1_clk";
				nvidia,pull = <TEGRA_PIN_PULL_NONE>;
				nvidia,tristate = <TEGRA_PIN_DISABLE>;
				nvidia,enable-input = <TEGRA_PIN_ENABLE>;
				nvidia,drv-type = <TEGRA_PIN_1X_DRIVER>;
				nvidia,e-io-od = <TEGRA_PIN_ENABLE>;
				nvidia,e-lpbk = <TEGRA_PIN_DISABLE>;
			};

			gen1_i2c_sda_pw3 {
				nvidia,pins = "gen1_i2c_sda_pw3";
				nvidia,function = "i2c1_dat";
				nvidia,pull = <TEGRA_PIN_PULL_NONE>;
				nvidia,tristate = <TEGRA_PIN_DISABLE>;
				nvidia,enable-input = <TEGRA_PIN_ENABLE>;
				nvidia,drv-type = <TEGRA_PIN_1X_DRIVER>;
				nvidia,e-io-od = <TEGRA_PIN_ENABLE>;
				nvidia,e-lpbk = <TEGRA_PIN_DISABLE>;
			};

			pwr_i2c_scl_pw6 {
				nvidia,pins = "pwr_i2c_scl_pw6";
				nvidia,function = "i2c5_clk";
				nvidia,pull = <TEGRA_PIN_PULL_NONE>;
				nvidia,tristate = <TEGRA_PIN_DISABLE>;
				nvidia,enable-input = <TEGRA_PIN_ENABLE>;
				nvidia,drv-type = <TEGRA_PIN_1X_DRIVER>;
				nvidia,e-io-od = <TEGRA_PIN_ENABLE>;
				nvidia,e-lpbk = <TEGRA_PIN_DISABLE>;
			};

			pwr_i2c_sda_pw7 {
				nvidia,pins = "pwr_i2c_sda_pw7";
				nvidia,function = "i2c5_dat";
				nvidia,pull = <TEGRA_PIN_PULL_NONE>;
				nvidia,tristate = <TEGRA_PIN_DISABLE>;
				nvidia,enable-input = <TEGRA_PIN_ENABLE>;
				nvidia,drv-type = <TEGRA_PIN_1X_DRIVER>;
				nvidia,e-io-od = <TEGRA_PIN_ENABLE>;
				nvidia,e-lpbk = <TEGRA_PIN_DISABLE>;
			};

			/* GPIO Pin Configuration */
			soc_gpio00_paa0 {
				nvidia,pins = "soc_gpio00_paa0";
				nvidia,function = "rsvd0";
				nvidia,pull = <TEGRA_PIN_PULL_NONE>;
				nvidia,tristate = <TEGRA_PIN_ENABLE>;
				nvidia,enable-input = <TEGRA_PIN_ENABLE>;
				nvidia,drv-type = <TEGRA_PIN_1X_DRIVER>;
				nvidia,e-io-od = <TEGRA_PIN_DISABLE>;
				nvidia,e-lpbk = <TEGRA_PIN_DISABLE>;
			};

			bootv_ctl_n_paa4 {
				nvidia,pins = "bootv_ctl_n_paa4";
				nvidia,function = "rsvd0";
				nvidia,pull = <TEGRA_PIN_PULL_UP>;
				nvidia,tristate = <TEGRA_PIN_ENABLE>;
				nvidia,enable-input = <TEGRA_PIN_ENABLE>;
				nvidia,drv-type = <TEGRA_PIN_1X_DRIVER>;
				nvidia,e-io-od = <TEGRA_PIN_DISABLE>;
				nvidia,e-lpbk = <TEGRA_PIN_DISABLE>;
			};

			power_on_paa5 {
				nvidia,pins = "power_on_paa5";
				nvidia,function = "rsvd0";
				nvidia,pull = <TEGRA_PIN_PULL_NONE>;
				nvidia,tristate = <TEGRA_PIN_ENABLE>;
				nvidia,enable-input = <TEGRA_PIN_ENABLE>;
				nvidia,drv-type = <TEGRA_PIN_1X_DRIVER>;
				nvidia,e-io-od = <TEGRA_PIN_DISABLE>;
				nvidia,e-lpbk = <TEGRA_PIN_DISABLE>;
			};

			soc_gpio07_paa7 {
				nvidia,pins = "soc_gpio07_paa7";
				nvidia,function = "rsvd0";
				nvidia,pull = <TEGRA_PIN_PULL_NONE>;
				nvidia,tristate = <TEGRA_PIN_ENABLE>;
				nvidia,enable-input = <TEGRA_PIN_ENABLE>;
				nvidia,drv-type = <TEGRA_PIN_1X_DRIVER>;
				nvidia,e-io-od = <TEGRA_PIN_DISABLE>;
				nvidia,e-lpbk = <TEGRA_PIN_DISABLE>;
			};

			soc_gpio08_pbb0 {
				nvidia,pins = "soc_gpio08_pbb0";
				nvidia,function = "rsvd0";
				nvidia,pull = <TEGRA_PIN_PULL_NONE>;
				nvidia,tristate = <TEGRA_PIN_ENABLE>;
				nvidia,enable-input = <TEGRA_PIN_ENABLE>;
				nvidia,drv-type = <TEGRA_PIN_1X_DRIVER>;
				nvidia,e-io-od = <TEGRA_PIN_DISABLE>;
				nvidia,e-lpbk = <TEGRA_PIN_DISABLE>;
			};

			soc_gpio09_pbb1 {
				nvidia,pins = "soc_gpio09_pbb1";
				nvidia,function = "rsvd0";
				nvidia,pull = <TEGRA_PIN_PULL_NONE>;
				nvidia,tristate = <TEGRA_PIN_ENABLE>;
				nvidia,enable-input = <TEGRA_PIN_ENABLE>;
				nvidia,drv-type = <TEGRA_PIN_1X_DRIVER>;
				nvidia,e-io-od = <TEGRA_PIN_DISABLE>;
				nvidia,e-lpbk = <TEGRA_PIN_DISABLE>;
			};

			spi2_sck_pcc7 {
				nvidia,pins = "spi2_sck_pcc7";
				nvidia,function = "rsvd1";
				nvidia,pull = <TEGRA_PIN_PULL_UP>;
				nvidia,tristate = <TEGRA_PIN_ENABLE>;
				nvidia,enable-input = <TEGRA_PIN_ENABLE>;
				nvidia,drv-type = <TEGRA_PIN_1X_DRIVER>;
				nvidia,e-io-od = <TEGRA_PIN_DISABLE>;
				nvidia,e-lpbk = <TEGRA_PIN_DISABLE>;
			};

			spi2_miso_pdd0 {
				nvidia,pins = "spi2_miso_pdd0";
				nvidia,function = "rsvd1";
				nvidia,pull = <TEGRA_PIN_PULL_UP>;
				nvidia,tristate = <TEGRA_PIN_ENABLE>;
				nvidia,enable-input = <TEGRA_PIN_ENABLE>;
				nvidia,drv-type = <TEGRA_PIN_1X_DRIVER>;
				nvidia,e-io-od = <TEGRA_PIN_DISABLE>;
				nvidia,e-lpbk = <TEGRA_PIN_DISABLE>;
			};

			spi2_mosi_pdd1 {
				nvidia,pins = "spi2_mosi_pdd1";
				nvidia,function = "rsvd1";
				nvidia,pull = <TEGRA_PIN_PULL_UP>;
				nvidia,tristate = <TEGRA_PIN_ENABLE>;
				nvidia,enable-input = <TEGRA_PIN_ENABLE>;
				nvidia,drv-type = <TEGRA_PIN_1X_DRIVER>;
				nvidia,e-io-od = <TEGRA_PIN_DISABLE>;
				nvidia,e-lpbk = <TEGRA_PIN_DISABLE>;
			};

			spi2_cs0_n_pdd2 {
				nvidia,pins = "spi2_cs0_n_pdd2";
				nvidia,function = "rsvd1";
				nvidia,pull = <TEGRA_PIN_PULL_UP>;
				nvidia,tristate = <TEGRA_PIN_ENABLE>;
				nvidia,enable-input = <TEGRA_PIN_ENABLE>;
				nvidia,drv-type = <TEGRA_PIN_1X_DRIVER>;
				nvidia,e-io-od = <TEGRA_PIN_DISABLE>;
				nvidia,e-lpbk = <TEGRA_PIN_DISABLE>;
			};

			soc_gpio21_pdd3 {
				nvidia,pins = "soc_gpio21_pdd3";
				nvidia,function = "rsvd0";
				nvidia,pull = <TEGRA_PIN_PULL_DOWN>;
				nvidia,tristate = <TEGRA_PIN_ENABLE>;
				nvidia,enable-input = <TEGRA_PIN_ENABLE>;
				nvidia,drv-type = <TEGRA_PIN_1X_DRIVER>;
				nvidia,e-io-od = <TEGRA_PIN_DISABLE>;
				nvidia,e-lpbk = <TEGRA_PIN_DISABLE>;
			};

			soc_gpio22_pdd4 {
				nvidia,pins = "soc_gpio22_pdd4";
				nvidia,function = "rsvd0";
				nvidia,pull = <TEGRA_PIN_PULL_DOWN>;
				nvidia,tristate = <TEGRA_PIN_ENABLE>;
				nvidia,enable-input = <TEGRA_PIN_ENABLE>;
				nvidia,drv-type = <TEGRA_PIN_1X_DRIVER>;
				nvidia,e-io-od = <TEGRA_PIN_DISABLE>;
				nvidia,e-lpbk = <TEGRA_PIN_DISABLE>;
			};

			soc_gpio24_pdd6 {
				nvidia,pins = "soc_gpio24_pdd6";
				nvidia,function = "rsvd0";
				nvidia,pull = <TEGRA_PIN_PULL_NONE>;
				nvidia,tristate = <TEGRA_PIN_DISABLE>;
				nvidia,enable-input = <TEGRA_PIN_DISABLE>;
				nvidia,drv-type = <TEGRA_PIN_1X_DRIVER>;
				nvidia,e-io-od = <TEGRA_PIN_DISABLE>;
				nvidia,e-lpbk = <TEGRA_PIN_DISABLE>;
			};

			soc_gpio27_pee1 {
				nvidia,pins = "soc_gpio27_pee1";
				nvidia,function = "rsvd0";
				nvidia,pull = <TEGRA_PIN_PULL_UP>;
				nvidia,tristate = <TEGRA_PIN_ENABLE>;
				nvidia,enable-input = <TEGRA_PIN_ENABLE>;
				nvidia,drv-type = <TEGRA_PIN_1X_DRIVER>;
				nvidia,e-io-od = <TEGRA_PIN_DISABLE>;
				nvidia,e-lpbk = <TEGRA_PIN_DISABLE>;
			};

			pex_wake_n_pc2 {
				nvidia,pins = "pex_wake_n_pc2";
				nvidia,function = "rsvd0";
				nvidia,pull = <TEGRA_PIN_PULL_NONE>;
				nvidia,tristate = <TEGRA_PIN_ENABLE>;
				nvidia,enable-input = <TEGRA_PIN_ENABLE>;
				nvidia,drv-type = <TEGRA_PIN_1X_DRIVER>;
				nvidia,e-io-od = <TEGRA_PIN_ENABLE>;
				nvidia,e-lpbk = <TEGRA_PIN_DISABLE>;
			};

			eth0_mdio_pd4 {
				nvidia,pins = "eth0_mdio_pd4";
				nvidia,function = "rsvd1";
				nvidia,pull = <TEGRA_PIN_PULL_NONE>;
				nvidia,tristate = <TEGRA_PIN_ENABLE>;
				nvidia,enable-input = <TEGRA_PIN_ENABLE>;
				nvidia,drv-type = <TEGRA_PIN_1X_DRIVER>;
				nvidia,e-io-od = <TEGRA_PIN_DISABLE>;
				nvidia,e-lpbk = <TEGRA_PIN_DISABLE>;
			};

			eth0_mdc_pd5 {
				nvidia,pins = "eth0_mdc_pd5";
				nvidia,function = "rsvd1";
				nvidia,pull = <TEGRA_PIN_PULL_NONE>;
				nvidia,tristate = <TEGRA_PIN_ENABLE>;
				nvidia,enable-input = <TEGRA_PIN_ENABLE>;
				nvidia,drv-type = <TEGRA_PIN_1X_DRIVER>;
				nvidia,e-io-od = <TEGRA_PIN_DISABLE>;
				nvidia,e-lpbk = <TEGRA_PIN_DISABLE>;
			};

			eth3_mdio_pd6 {
				nvidia,pins = "eth3_mdio_pd6";
				nvidia,function = "rsvd1";
				nvidia,pull = <TEGRA_PIN_PULL_NONE>;
				nvidia,tristate = <TEGRA_PIN_ENABLE>;
				nvidia,enable-input = <TEGRA_PIN_ENABLE>;
				nvidia,drv-type = <TEGRA_PIN_1X_DRIVER>;
				nvidia,e-io-od = <TEGRA_PIN_DISABLE>;
				nvidia,e-lpbk = <TEGRA_PIN_DISABLE>;
			};

			eth3_mdc_pd7 {
				nvidia,pins = "eth3_mdc_pd7";
				nvidia,function = "rsvd1";
				nvidia,pull = <TEGRA_PIN_PULL_NONE>;
				nvidia,tristate = <TEGRA_PIN_ENABLE>;
				nvidia,enable-input = <TEGRA_PIN_ENABLE>;
				nvidia,drv-type = <TEGRA_PIN_1X_DRIVER>;
				nvidia,e-io-od = <TEGRA_PIN_DISABLE>;
				nvidia,e-lpbk = <TEGRA_PIN_DISABLE>;
			};

			eth1_mdio_pe0 {
				nvidia,pins = "eth1_mdio_pe0";
				nvidia,function = "rsvd1";
				nvidia,pull = <TEGRA_PIN_PULL_NONE>;
				nvidia,tristate = <TEGRA_PIN_DISABLE>;
				nvidia,enable-input = <TEGRA_PIN_DISABLE>;
				nvidia,drv-type = <TEGRA_PIN_1X_DRIVER>;
				nvidia,e-io-od = <TEGRA_PIN_DISABLE>;
				nvidia,e-lpbk = <TEGRA_PIN_DISABLE>;
			};

			can0_stb_pab2 {
				nvidia,pins = "can0_stb_pab2";
				nvidia,function = "rsvd0";
				nvidia,pull = <TEGRA_PIN_PULL_NONE>;
				nvidia,tristate = <TEGRA_PIN_DISABLE>;
				nvidia,enable-input = <TEGRA_PIN_DISABLE>;
				nvidia,drv-type = <TEGRA_PIN_DEFAULT_DRIVE_1X>;
				nvidia,e-lpbk = <TEGRA_PIN_DISABLE>;
			};

			can0_en_pab3 {
				nvidia,pins = "can0_en_pab3";
				nvidia,function = "rsvd0";
				nvidia,pull = <TEGRA_PIN_PULL_NONE>;
				nvidia,tristate = <TEGRA_PIN_DISABLE>;
				nvidia,enable-input = <TEGRA_PIN_DISABLE>;
				nvidia,drv-type = <TEGRA_PIN_DEFAULT_DRIVE_1X>;
				nvidia,e-lpbk = <TEGRA_PIN_DISABLE>;
			};

			can0_err_pab4 {
				nvidia,pins = "can0_err_pab4";
				nvidia,function = "rsvd0";
				nvidia,pull = <TEGRA_PIN_PULL_NONE>;
				nvidia,tristate = <TEGRA_PIN_ENABLE>;
				nvidia,enable-input = <TEGRA_PIN_ENABLE>;
				nvidia,drv-type = <TEGRA_PIN_DEFAULT_DRIVE_1X>;
				nvidia,e-lpbk = <TEGRA_PIN_DISABLE>;
			};

			can1_stb_pac2 {
				nvidia,pins = "can1_stb_pac2";
				nvidia,function = "rsvd0";
				nvidia,pull = <TEGRA_PIN_PULL_NONE>;
				nvidia,tristate = <TEGRA_PIN_DISABLE>;
				nvidia,enable-input = <TEGRA_PIN_DISABLE>;
				nvidia,drv-type = <TEGRA_PIN_DEFAULT_DRIVE_1X>;
				nvidia,e-lpbk = <TEGRA_PIN_DISABLE>;
			};

			can1_en_pac3 {
				nvidia,pins = "can1_en_pac3";
				nvidia,function = "rsvd0";
				nvidia,pull = <TEGRA_PIN_PULL_NONE>;
				nvidia,tristate = <TEGRA_PIN_ENABLE>;
				nvidia,enable-input = <TEGRA_PIN_ENABLE>;
				nvidia,drv-type = <TEGRA_PIN_DEFAULT_DRIVE_1X>;
				nvidia,e-lpbk = <TEGRA_PIN_DISABLE>;
			};

			soc_gpio250_pf0 {
				nvidia,pins = "soc_gpio250_pf0";
				nvidia,function = "dca_vsync";
				nvidia,pull = <TEGRA_PIN_PULL_NONE>;
				nvidia,tristate = <TEGRA_PIN_DISABLE>;
				nvidia,enable-input = <TEGRA_PIN_DISABLE>;
				nvidia,drv-type = <TEGRA_PIN_1X_DRIVER>;
				nvidia,e-io-od = <TEGRA_PIN_DISABLE>;
				nvidia,e-lpbk = <TEGRA_PIN_DISABLE>;
			};

			soc_gpio251_pf1 {
				nvidia,pins = "soc_gpio251_pf1";
				nvidia,function = "dca_hsync";
				nvidia,pull = <TEGRA_PIN_PULL_NONE>;
				nvidia,tristate = <TEGRA_PIN_DISABLE>;
				nvidia,enable-input = <TEGRA_PIN_DISABLE>;
				nvidia,drv-type = <TEGRA_PIN_1X_DRIVER>;
				nvidia,e-io-od = <TEGRA_PIN_DISABLE>;
				nvidia,e-lpbk = <TEGRA_PIN_DISABLE>;
			};

			soc_gpio252_pf2 {
				nvidia,pins = "soc_gpio252_pf2";
				nvidia,function = "rsvd0";
				nvidia,pull = <TEGRA_PIN_PULL_NONE>;
				nvidia,tristate = <TEGRA_PIN_DISABLE>;
				nvidia,enable-input = <TEGRA_PIN_DISABLE>;
				nvidia,drv-type = <TEGRA_PIN_1X_DRIVER>;
				nvidia,e-io-od = <TEGRA_PIN_DISABLE>;
				nvidia,e-lpbk = <TEGRA_PIN_DISABLE>;
			};

			dp_aux_ch1_hpd_pf4 {
				nvidia,pins = "dp_aux_ch1_hpd_pf4";
				nvidia,function = "dp_aux_ch1_hpd";
				nvidia,pull = <TEGRA_PIN_PULL_NONE>;
				nvidia,tristate = <TEGRA_PIN_ENABLE>;
				nvidia,enable-input = <TEGRA_PIN_ENABLE>;
				nvidia,drv-type = <TEGRA_PIN_1X_DRIVER>;
				nvidia,e-io-od = <TEGRA_PIN_DISABLE>;
				nvidia,e-lpbk = <TEGRA_PIN_DISABLE>;
			};

			cpu_pwr_req_ph0 {
				nvidia,pins = "cpu_pwr_req_ph0";
				nvidia,function = "rsvd0";
				nvidia,pull = <TEGRA_PIN_PULL_NONE>;
				nvidia,tristate = <TEGRA_PIN_DISABLE>;
				nvidia,enable-input = <TEGRA_PIN_DISABLE>;
				nvidia,drv-type = <TEGRA_PIN_1X_DRIVER>;
				nvidia,e-io-od = <TEGRA_PIN_DISABLE>;
				nvidia,e-lpbk = <TEGRA_PIN_DISABLE>;
			};

			gpu_pwr_req_ph1 {
				nvidia,pins = "gpu_pwr_req_ph1";
				nvidia,function = "rsvd0";
				nvidia,pull = <TEGRA_PIN_PULL_NONE>;
				nvidia,tristate = <TEGRA_PIN_DISABLE>;
				nvidia,enable-input = <TEGRA_PIN_DISABLE>;
				nvidia,drv-type = <TEGRA_PIN_1X_DRIVER>;
				nvidia,e-io-od = <TEGRA_PIN_DISABLE>;
				nvidia,e-lpbk = <TEGRA_PIN_DISABLE>;
			};

			uart10_rts_n_ph4 {
				nvidia,pins = "uart10_rts_n_ph4";
				nvidia,function = "rsvd1";
				nvidia,pull = <TEGRA_PIN_PULL_NONE>;
				nvidia,tristate = <TEGRA_PIN_DISABLE>;
				nvidia,enable-input = <TEGRA_PIN_DISABLE>;
				nvidia,drv-type = <TEGRA_PIN_1X_DRIVER>;
				nvidia,e-io-od = <TEGRA_PIN_DISABLE>;
				nvidia,e-lpbk = <TEGRA_PIN_DISABLE>;
			};

			uart10_cts_n_ph5 {
				nvidia,pins = "uart10_cts_n_ph5";
				nvidia,function = "rsvd1";
				nvidia,pull = <TEGRA_PIN_PULL_NONE>;
				nvidia,tristate = <TEGRA_PIN_ENABLE>;
				nvidia,enable-input = <TEGRA_PIN_ENABLE>;
				nvidia,drv-type = <TEGRA_PIN_1X_DRIVER>;
				nvidia,e-io-od = <TEGRA_PIN_DISABLE>;
				nvidia,e-lpbk = <TEGRA_PIN_DISABLE>;
			};

			soc_gpio127_pl3 {
				nvidia,pins = "soc_gpio127_pl3";
				nvidia,function = "rsvd1";
				nvidia,pull = <TEGRA_PIN_PULL_NONE>;
				nvidia,tristate = <TEGRA_PIN_DISABLE>;
				nvidia,enable-input = <TEGRA_PIN_DISABLE>;
				nvidia,drv-type = <TEGRA_PIN_1X_DRIVER>;
				nvidia,e-io-od = <TEGRA_PIN_DISABLE>;
				nvidia,e-lpbk = <TEGRA_PIN_DISABLE>;
			};

			soc_gpio139_pp1 {
				nvidia,pins = "soc_gpio139_pp1";
				nvidia,function = "rsvd0";
				nvidia,pull = <TEGRA_PIN_PULL_NONE>;
				nvidia,tristate = <TEGRA_PIN_ENABLE>;
				nvidia,enable-input = <TEGRA_PIN_ENABLE>;
				nvidia,drv-type = <TEGRA_PIN_1X_DRIVER>;
				nvidia,e-io-od = <TEGRA_PIN_DISABLE>;
				nvidia,e-lpbk = <TEGRA_PIN_DISABLE>;
			};

			spi5_sck_pq2 {
				nvidia,pins = "spi5_sck_pq2";
				nvidia,function = "rsvd1";
				nvidia,pull = <TEGRA_PIN_PULL_NONE>;
				nvidia,tristate = <TEGRA_PIN_DISABLE>;
				nvidia,enable-input = <TEGRA_PIN_DISABLE>;
				nvidia,drv-type = <TEGRA_PIN_1X_DRIVER>;
				nvidia,e-io-od = <TEGRA_PIN_DISABLE>;
				nvidia,e-lpbk = <TEGRA_PIN_DISABLE>;
			};

			spi5_mosi_pq4 {
				nvidia,pins = "spi5_mosi_pq4";
				nvidia,function = "rsvd1";
				nvidia,pull = <TEGRA_PIN_PULL_NONE>;
				nvidia,tristate = <TEGRA_PIN_DISABLE>;
				nvidia,enable-input = <TEGRA_PIN_DISABLE>;
				nvidia,drv-type = <TEGRA_PIN_1X_DRIVER>;
				nvidia,e-io-od = <TEGRA_PIN_DISABLE>;
				nvidia,e-lpbk = <TEGRA_PIN_DISABLE>;
			};

			soc_gpio153_pq7 {
				nvidia,pins = "soc_gpio153_pq7";
				nvidia,function = "rsvd0";
				nvidia,pull = <TEGRA_PIN_PULL_UP>;
				nvidia,tristate = <TEGRA_PIN_ENABLE>;
				nvidia,enable-input = <TEGRA_PIN_ENABLE>;
				nvidia,drv-type = <TEGRA_PIN_1X_DRIVER>;
				nvidia,e-io-od = <TEGRA_PIN_DISABLE>;
				nvidia,e-lpbk = <TEGRA_PIN_DISABLE>;
			};

			soc_gpio155_pr1 {
				nvidia,pins = "soc_gpio155_pr1";
				nvidia,function = "rsvd0";
				nvidia,pull = <TEGRA_PIN_PULL_NONE>;
				nvidia,tristate = <TEGRA_PIN_DISABLE>;
				nvidia,enable-input = <TEGRA_PIN_DISABLE>;
				nvidia,drv-type = <TEGRA_PIN_1X_DRIVER>;
				nvidia,e-io-od = <TEGRA_PIN_DISABLE>;
				nvidia,e-lpbk = <TEGRA_PIN_DISABLE>;
			};

			soc_gpio350_ps0 {
				nvidia,pins = "soc_gpio350_ps0";
				nvidia,function = "rsvd0";
				nvidia,pull = <TEGRA_PIN_PULL_UP>;
				nvidia,tristate = <TEGRA_PIN_ENABLE>;
				nvidia,enable-input = <TEGRA_PIN_ENABLE>;
				nvidia,drv-type = <TEGRA_PIN_1X_DRIVER>;
				nvidia,e-io-od = <TEGRA_PIN_DISABLE>;
				nvidia,e-lpbk = <TEGRA_PIN_DISABLE>;
			};

			soc_gpio351_ps1 {
				nvidia,pins = "soc_gpio351_ps1";
				nvidia,function = "rsvd0";
				nvidia,pull = <TEGRA_PIN_PULL_NONE>;
				nvidia,tristate = <TEGRA_PIN_ENABLE>;
				nvidia,enable-input = <TEGRA_PIN_ENABLE>;
				nvidia,drv-type = <TEGRA_PIN_1X_DRIVER>;
				nvidia,e-io-od = <TEGRA_PIN_DISABLE>;
				nvidia,e-lpbk = <TEGRA_PIN_DISABLE>;
			};

			soc_gpio192_pt6 {
				nvidia,pins = "soc_gpio192_pt6";
				nvidia,function = "rsvd0";
				nvidia,pull = <TEGRA_PIN_PULL_UP>;
				nvidia,tristate = <TEGRA_PIN_ENABLE>;
				nvidia,enable-input = <TEGRA_PIN_ENABLE>;
				nvidia,drv-type = <TEGRA_PIN_1X_DRIVER>;
				nvidia,e-io-od = <TEGRA_PIN_DISABLE>;
				nvidia,e-lpbk = <TEGRA_PIN_DISABLE>;
			};

			soc_gpio170_pu0 {
				nvidia,pins = "soc_gpio170_pu0";
				nvidia,function = "rsvd0";
				nvidia,pull = <TEGRA_PIN_PULL_DOWN>;
				nvidia,tristate = <TEGRA_PIN_ENABLE>;
				nvidia,enable-input = <TEGRA_PIN_ENABLE>;
				nvidia,drv-type = <TEGRA_PIN_1X_DRIVER>;
				nvidia,e-io-od = <TEGRA_PIN_DISABLE>;
				nvidia,e-lpbk = <TEGRA_PIN_DISABLE>;
			};

			soc_gpio173_pu3 {
				nvidia,pins = "soc_gpio173_pu3";
				nvidia,function = "rsvd0";
				nvidia,pull = <TEGRA_PIN_PULL_NONE>;
				nvidia,tristate = <TEGRA_PIN_DISABLE>;
				nvidia,enable-input = <TEGRA_PIN_DISABLE>;
				nvidia,drv-type = <TEGRA_PIN_1X_DRIVER>;
				nvidia,e-io-od = <TEGRA_PIN_DISABLE>;
				nvidia,e-lpbk = <TEGRA_PIN_DISABLE>;
			};

			soc_gpio174_pu4 {
				nvidia,pins = "soc_gpio174_pu4";
				nvidia,function = "rsvd0";
				nvidia,pull = <TEGRA_PIN_PULL_UP>;
				nvidia,tristate = <TEGRA_PIN_ENABLE>;
				nvidia,enable-input = <TEGRA_PIN_ENABLE>;
				nvidia,drv-type = <TEGRA_PIN_1X_DRIVER>;
				nvidia,e-io-od = <TEGRA_PIN_DISABLE>;
				nvidia,e-lpbk = <TEGRA_PIN_DISABLE>;
			};

			soc_gpio176_pu6 {
				nvidia,pins = "soc_gpio176_pu6";
				nvidia,function = "rsvd0";
				nvidia,pull = <TEGRA_PIN_PULL_NONE>;
				nvidia,tristate = <TEGRA_PIN_DISABLE>;
				nvidia,enable-input = <TEGRA_PIN_DISABLE>;
				nvidia,drv-type = <TEGRA_PIN_1X_DRIVER>;
				nvidia,e-io-od = <TEGRA_PIN_DISABLE>;
				nvidia,e-lpbk = <TEGRA_PIN_DISABLE>;
			};

			soc_gpio177_pu7 {
				nvidia,pins = "soc_gpio177_pu7";
				nvidia,function = "rsvd0";
				nvidia,pull = <TEGRA_PIN_PULL_DOWN>;
				nvidia,tristate = <TEGRA_PIN_ENABLE>;
				nvidia,enable-input = <TEGRA_PIN_ENABLE>;
				nvidia,drv-type = <TEGRA_PIN_1X_DRIVER>;
				nvidia,e-io-od = <TEGRA_PIN_DISABLE>;
				nvidia,e-lpbk = <TEGRA_PIN_DISABLE>;
			};

			pwm10_pv1 {
				nvidia,pins = "pwm10_pv1";
				nvidia,function = "rsvd3";
				nvidia,pull = <TEGRA_PIN_PULL_NONE>;
				nvidia,tristate = <TEGRA_PIN_DISABLE>;
				nvidia,enable-input = <TEGRA_PIN_DISABLE>;
				nvidia,drv-type = <TEGRA_PIN_1X_DRIVER>;
				nvidia,e-io-od = <TEGRA_PIN_DISABLE>;
				nvidia,e-lpbk = <TEGRA_PIN_DISABLE>;
			};

			uart4_cts_n_pv5 {
				nvidia,pins = "uart4_cts_n_pv5";
				nvidia,function = "rsvd1";
				nvidia,pull = <TEGRA_PIN_PULL_NONE>;
				nvidia,tristate = <TEGRA_PIN_DISABLE>;
				nvidia,enable-input = <TEGRA_PIN_DISABLE>;
				nvidia,drv-type = <TEGRA_PIN_1X_DRIVER>;
				nvidia,e-io-od = <TEGRA_PIN_DISABLE>;
				nvidia,e-lpbk = <TEGRA_PIN_DISABLE>;
			};

			gen0_i2c_scl_pw4 {
				nvidia,pins = "gen0_i2c_scl_pw4";
				nvidia,function = "rsvd1";
				nvidia,pull = <TEGRA_PIN_PULL_NONE>;
				nvidia,tristate = <TEGRA_PIN_DISABLE>;
				nvidia,enable-input = <TEGRA_PIN_DISABLE>;
				nvidia,drv-type = <TEGRA_PIN_1X_DRIVER>;
				nvidia,e-io-od = <TEGRA_PIN_DISABLE>;
				nvidia,e-lpbk = <TEGRA_PIN_DISABLE>;
			};

			gen0_i2c_sda_pw5 {
				nvidia,pins = "gen0_i2c_sda_pw5";
				nvidia,function = "rsvd1";
				nvidia,pull = <TEGRA_PIN_PULL_NONE>;
				nvidia,tristate = <TEGRA_PIN_ENABLE>;
				nvidia,enable-input = <TEGRA_PIN_ENABLE>;
				nvidia,drv-type = <TEGRA_PIN_1X_DRIVER>;
				nvidia,e-io-od = <TEGRA_PIN_DISABLE>;
				nvidia,e-lpbk = <TEGRA_PIN_DISABLE>;
			};

			soc_gpio271_py1 {
				nvidia,pins = "soc_gpio271_py1";
				nvidia,function = "rsvd0";
				nvidia,pull = <TEGRA_PIN_PULL_NONE>;
				nvidia,tristate = <TEGRA_PIN_DISABLE>;
				nvidia,enable-input = <TEGRA_PIN_DISABLE>;
				nvidia,drv-type = <TEGRA_PIN_1X_DRIVER>;
				nvidia,e-io-od = <TEGRA_PIN_DISABLE>;
				nvidia,e-lpbk = <TEGRA_PIN_DISABLE>;
			};

			soc_gpio273_py3 {
				nvidia,pins = "soc_gpio273_py3";
				nvidia,function = "rsvd0";
				nvidia,pull = <TEGRA_PIN_PULL_UP>;
				nvidia,tristate = <TEGRA_PIN_ENABLE>;
				nvidia,enable-input = <TEGRA_PIN_ENABLE>;
				nvidia,drv-type = <TEGRA_PIN_1X_DRIVER>;
				nvidia,e-io-od = <TEGRA_PIN_DISABLE>;
				nvidia,e-lpbk = <TEGRA_PIN_DISABLE>;
			};

			soc_gpio274_py4 {
				nvidia,pins = "soc_gpio274_py4";
				nvidia,function = "rsvd0";
				nvidia,pull = <TEGRA_PIN_PULL_UP>;
				nvidia,tristate = <TEGRA_PIN_ENABLE>;
				nvidia,enable-input = <TEGRA_PIN_ENABLE>;
				nvidia,drv-type = <TEGRA_PIN_1X_DRIVER>;
				nvidia,e-io-od = <TEGRA_PIN_DISABLE>;
				nvidia,e-lpbk = <TEGRA_PIN_DISABLE>;
			};

			soc_gpio275_py5 {
				nvidia,pins = "soc_gpio275_py5";
				nvidia,function = "rsvd0";
				nvidia,pull = <TEGRA_PIN_PULL_NONE>;
				nvidia,tristate = <TEGRA_PIN_DISABLE>;
				nvidia,enable-input = <TEGRA_PIN_DISABLE>;
				nvidia,drv-type = <TEGRA_PIN_1X_DRIVER>;
				nvidia,e-io-od = <TEGRA_PIN_DISABLE>;
				nvidia,e-lpbk = <TEGRA_PIN_DISABLE>;
			};

			soc_gpio279_pz1 {
				nvidia,pins = "soc_gpio279_pz1";
				nvidia,function = "rsvd1";
				nvidia,pull = <TEGRA_PIN_PULL_NONE>;
				nvidia,tristate = <TEGRA_PIN_ENABLE>;
				nvidia,enable-input = <TEGRA_PIN_ENABLE>;
				nvidia,drv-type = <TEGRA_PIN_1X_DRIVER>;
				nvidia,e-io-od = <TEGRA_PIN_DISABLE>;
				nvidia,e-lpbk = <TEGRA_PIN_DISABLE>;
			};

			soc_gpio283_pz5 {
				nvidia,pins = "soc_gpio283_pz5";
				nvidia,function = "rsvd0";
				nvidia,pull = <TEGRA_PIN_PULL_NONE>;
				nvidia,tristate = <TEGRA_PIN_ENABLE>;
				nvidia,enable-input = <TEGRA_PIN_ENABLE>;
				nvidia,drv-type = <TEGRA_PIN_1X_DRIVER>;
				nvidia,e-io-od = <TEGRA_PIN_DISABLE>;
				nvidia,e-lpbk = <TEGRA_PIN_DISABLE>;
			};

			soc_gpio284_pz6 {
				nvidia,pins = "soc_gpio284_pz6";
				nvidia,function = "rsvd0";
				nvidia,pull = <TEGRA_PIN_PULL_NONE>;
				nvidia,tristate = <TEGRA_PIN_ENABLE>;
				nvidia,enable-input = <TEGRA_PIN_ENABLE>;
				nvidia,drv-type = <TEGRA_PIN_1X_DRIVER>;
				nvidia,e-io-od = <TEGRA_PIN_DISABLE>;
				nvidia,e-lpbk = <TEGRA_PIN_DISABLE>;
			};

			soc_gpio285_pz7 {
				nvidia,pins = "soc_gpio285_pz7";
				nvidia,function = "rsvd0";
				nvidia,pull = <TEGRA_PIN_PULL_UP>;
				nvidia,tristate = <TEGRA_PIN_ENABLE>;
				nvidia,enable-input = <TEGRA_PIN_ENABLE>;
				nvidia,drv-type = <TEGRA_PIN_1X_DRIVER>;
				nvidia,e-io-od = <TEGRA_PIN_DISABLE>;
				nvidia,e-lpbk = <TEGRA_PIN_DISABLE>;
			};

			soc_gpio287_pal1 {
				nvidia,pins = "soc_gpio287_pal1";
				nvidia,function = "rsvd0";
				nvidia,pull = <TEGRA_PIN_PULL_NONE>;
				nvidia,tristate = <TEGRA_PIN_DISABLE>;
				nvidia,enable-input = <TEGRA_PIN_DISABLE>;
				nvidia,drv-type = <TEGRA_PIN_1X_DRIVER>;
				nvidia,e-io-od = <TEGRA_PIN_DISABLE>;
				nvidia,e-lpbk = <TEGRA_PIN_DISABLE>;
			};
		};

	unused_lowpower {
			vcomp_alert_paa1 {
				nvidia,pins = "vcomp_alert_paa1";
				nvidia,function = "rsvd1";
				nvidia,pull = <TEGRA_PIN_PULL_DOWN>;
				nvidia,tristate = <TEGRA_PIN_ENABLE>;
				nvidia,enable-input = <TEGRA_PIN_DISABLE>;
				nvidia,drv-type = <TEGRA_PIN_1X_DRIVER>;
				nvidia,e-io-od = <TEGRA_PIN_DISABLE>;
				nvidia,e-lpbk = <TEGRA_PIN_DISABLE>;
			};

			ao_retention_n_paa2 {
				nvidia,pins = "ao_retention_n_paa2";
				nvidia,function = "rsvd0";
				nvidia,pull = <TEGRA_PIN_PULL_DOWN>;
				nvidia,tristate = <TEGRA_PIN_ENABLE>;
				nvidia,enable-input = <TEGRA_PIN_DISABLE>;
				nvidia,drv-type = <TEGRA_PIN_1X_DRIVER>;
				nvidia,e-io-od = <TEGRA_PIN_DISABLE>;
				nvidia,e-lpbk = <TEGRA_PIN_DISABLE>;
			};

			soc_gpio113_pb6 {
				nvidia,pins = "soc_gpio113_pb6";
				nvidia,function = "rsvd1";
				nvidia,pull = <TEGRA_PIN_PULL_DOWN>;
				nvidia,tristate = <TEGRA_PIN_ENABLE>;
				nvidia,enable-input = <TEGRA_PIN_DISABLE>;
				nvidia,drv-type = <TEGRA_PIN_1X_DRIVER>;
				nvidia,e-io-od = <TEGRA_PIN_DISABLE>;
				nvidia,e-lpbk = <TEGRA_PIN_DISABLE>;
			};

			soc_gpio114_pb7 {
				nvidia,pins = "soc_gpio114_pb7";
				nvidia,function = "rsvd1";
				nvidia,pull = <TEGRA_PIN_PULL_DOWN>;
				nvidia,tristate = <TEGRA_PIN_ENABLE>;
				nvidia,enable-input = <TEGRA_PIN_DISABLE>;
				nvidia,drv-type = <TEGRA_PIN_1X_DRIVER>;
				nvidia,e-io-od = <TEGRA_PIN_DISABLE>;
				nvidia,e-lpbk = <TEGRA_PIN_DISABLE>;
			};

			sgmii0_sma_mdio_pc0 {
				nvidia,pins = "sgmii0_sma_mdio_pc0";
				nvidia,function = "rsvd1";
				nvidia,pull = <TEGRA_PIN_PULL_DOWN>;
				nvidia,tristate = <TEGRA_PIN_ENABLE>;
				nvidia,enable-input = <TEGRA_PIN_DISABLE>;
				nvidia,drv-type = <TEGRA_PIN_1X_DRIVER>;
				nvidia,e-io-od = <TEGRA_PIN_DISABLE>;
				nvidia,e-lpbk = <TEGRA_PIN_DISABLE>;
			};

			sgmii0_sma_mdc_pc1 {
				nvidia,pins = "sgmii0_sma_mdc_pc1";
				nvidia,function = "rsvd1";
				nvidia,pull = <TEGRA_PIN_PULL_DOWN>;
				nvidia,tristate = <TEGRA_PIN_ENABLE>;
				nvidia,enable-input = <TEGRA_PIN_DISABLE>;
				nvidia,drv-type = <TEGRA_PIN_1X_DRIVER>;
				nvidia,e-io-od = <TEGRA_PIN_DISABLE>;
				nvidia,e-lpbk = <TEGRA_PIN_DISABLE>;
			};

			pex_l4_clkreq_n_pd0 {
				nvidia,pins = "pex_l4_clkreq_n_pd0";
				nvidia,function = "rsvd1";
				nvidia,pull = <TEGRA_PIN_PULL_DOWN>;
				nvidia,tristate = <TEGRA_PIN_ENABLE>;
				nvidia,enable-input = <TEGRA_PIN_DISABLE>;
				nvidia,drv-type = <TEGRA_PIN_1X_DRIVER>;
				nvidia,e-io-od = <TEGRA_PIN_ENABLE>;
				nvidia,e-lpbk = <TEGRA_PIN_DISABLE>;
			};

			pex_l4_rst_n_pd1 {
				nvidia,pins = "pex_l4_rst_n_pd1";
				nvidia,function = "rsvd1";
				nvidia,pull = <TEGRA_PIN_PULL_DOWN>;
				nvidia,tristate = <TEGRA_PIN_ENABLE>;
				nvidia,enable-input = <TEGRA_PIN_DISABLE>;
				nvidia,drv-type = <TEGRA_PIN_1X_DRIVER>;
				nvidia,e-io-od = <TEGRA_PIN_ENABLE>;
				nvidia,e-lpbk = <TEGRA_PIN_DISABLE>;
			};

			eth1_mdc_pe1 {
				nvidia,pins = "eth1_mdc_pe1";
				nvidia,function = "rsvd1";
				nvidia,pull = <TEGRA_PIN_PULL_DOWN>;
				nvidia,tristate = <TEGRA_PIN_ENABLE>;
				nvidia,enable-input = <TEGRA_PIN_DISABLE>;
				nvidia,drv-type = <TEGRA_PIN_1X_DRIVER>;
				nvidia,e-io-od = <TEGRA_PIN_DISABLE>;
				nvidia,e-lpbk = <TEGRA_PIN_DISABLE>;
			};

			eth2_mdio_pe2 {
				nvidia,pins = "eth2_mdio_pe2";
				nvidia,function = "rsvd1";
				nvidia,pull = <TEGRA_PIN_PULL_DOWN>;
				nvidia,tristate = <TEGRA_PIN_ENABLE>;
				nvidia,enable-input = <TEGRA_PIN_DISABLE>;
				nvidia,drv-type = <TEGRA_PIN_1X_DRIVER>;
				nvidia,e-io-od = <TEGRA_PIN_DISABLE>;
				nvidia,e-lpbk = <TEGRA_PIN_DISABLE>;
			};

			eth2_mdc_pe3 {
				nvidia,pins = "eth2_mdc_pe3";
				nvidia,function = "rsvd1";
				nvidia,pull = <TEGRA_PIN_PULL_DOWN>;
				nvidia,tristate = <TEGRA_PIN_ENABLE>;
				nvidia,enable-input = <TEGRA_PIN_DISABLE>;
				nvidia,drv-type = <TEGRA_PIN_1X_DRIVER>;
				nvidia,e-io-od = <TEGRA_PIN_DISABLE>;
				nvidia,e-lpbk = <TEGRA_PIN_DISABLE>;
			};

			can1_err_pac4 {
				nvidia,pins = "can1_err_pac4";
				nvidia,function = "rsvd0";
				nvidia,pull = <TEGRA_PIN_PULL_DOWN>;
				nvidia,tristate = <TEGRA_PIN_ENABLE>;
				nvidia,enable-input = <TEGRA_PIN_DISABLE>;
				nvidia,drv-type = <TEGRA_PIN_DEFAULT_DRIVE_1X>;
				nvidia,e-lpbk = <TEGRA_PIN_DISABLE>;
			};

			soc_error_paf0 {
				nvidia,pins = "soc_error_paf0";
				nvidia,function = "rsvd1";
				nvidia,pull = <TEGRA_PIN_PULL_DOWN>;
				nvidia,tristate = <TEGRA_PIN_ENABLE>;
				nvidia,enable-input = <TEGRA_PIN_DISABLE>;
				nvidia,drv-type = <TEGRA_PIN_1X_DRIVER>;
				nvidia,e-io-od = <TEGRA_PIN_DISABLE>;
				nvidia,e-lpbk = <TEGRA_PIN_DISABLE>;
			};

			spi7_sck_paf1 {
				nvidia,pins = "spi7_sck_paf1";
				nvidia,function = "rsvd1";
				nvidia,pull = <TEGRA_PIN_PULL_DOWN>;
				nvidia,tristate = <TEGRA_PIN_ENABLE>;
				nvidia,enable-input = <TEGRA_PIN_DISABLE>;
				nvidia,drv-type = <TEGRA_PIN_2X_DRIVER>;
				nvidia,e-io-od = <TEGRA_PIN_DISABLE>;
				nvidia,e-lpbk = <TEGRA_PIN_DISABLE>;
			};

			spi7_miso_paf2 {
				nvidia,pins = "spi7_miso_paf2";
				nvidia,function = "rsvd1";
				nvidia,pull = <TEGRA_PIN_PULL_DOWN>;
				nvidia,tristate = <TEGRA_PIN_ENABLE>;
				nvidia,enable-input = <TEGRA_PIN_DISABLE>;
				nvidia,drv-type = <TEGRA_PIN_2X_DRIVER>;
				nvidia,e-io-od = <TEGRA_PIN_DISABLE>;
				nvidia,e-lpbk = <TEGRA_PIN_DISABLE>;
			};

			spi7_mosi_paf3 {
				nvidia,pins = "spi7_mosi_paf3";
				nvidia,function = "rsvd1";
				nvidia,pull = <TEGRA_PIN_PULL_DOWN>;
				nvidia,tristate = <TEGRA_PIN_ENABLE>;
				nvidia,enable-input = <TEGRA_PIN_DISABLE>;
				nvidia,drv-type = <TEGRA_PIN_2X_DRIVER>;
				nvidia,e-io-od = <TEGRA_PIN_DISABLE>;
				nvidia,e-lpbk = <TEGRA_PIN_DISABLE>;
			};

			spi7_cs0_n_paf4 {
				nvidia,pins = "spi7_cs0_n_paf4";
				nvidia,function = "rsvd1";
				nvidia,pull = <TEGRA_PIN_PULL_DOWN>;
				nvidia,tristate = <TEGRA_PIN_ENABLE>;
				nvidia,enable-input = <TEGRA_PIN_DISABLE>;
				nvidia,drv-type = <TEGRA_PIN_2X_DRIVER>;
				nvidia,e-io-od = <TEGRA_PIN_DISABLE>;
				nvidia,e-lpbk = <TEGRA_PIN_DISABLE>;
			};

			soc_gpio225_paf5 {
				nvidia,pins = "soc_gpio225_paf5";
				nvidia,function = "rsvd0";
				nvidia,pull = <TEGRA_PIN_PULL_DOWN>;
				nvidia,tristate = <TEGRA_PIN_ENABLE>;
				nvidia,enable-input = <TEGRA_PIN_DISABLE>;
				nvidia,drv-type = <TEGRA_PIN_1X_DRIVER>;
				nvidia,e-io-od = <TEGRA_PIN_DISABLE>;
				nvidia,e-lpbk = <TEGRA_PIN_DISABLE>;
			};

			soc_gpio226_paf6 {
				nvidia,pins = "soc_gpio226_paf6";
				nvidia,function = "rsvd0";
				nvidia,pull = <TEGRA_PIN_PULL_DOWN>;
				nvidia,tristate = <TEGRA_PIN_ENABLE>;
				nvidia,enable-input = <TEGRA_PIN_DISABLE>;
				nvidia,drv-type = <TEGRA_PIN_1X_DRIVER>;
				nvidia,e-io-od = <TEGRA_PIN_DISABLE>;
				nvidia,e-lpbk = <TEGRA_PIN_DISABLE>;
			};

			spi8_sck_paf7 {
				nvidia,pins = "spi8_sck_paf7";
				nvidia,function = "rsvd1";
				nvidia,pull = <TEGRA_PIN_PULL_DOWN>;
				nvidia,tristate = <TEGRA_PIN_ENABLE>;
				nvidia,enable-input = <TEGRA_PIN_DISABLE>;
				nvidia,drv-type = <TEGRA_PIN_1X_DRIVER>;
				nvidia,e-io-od = <TEGRA_PIN_DISABLE>;
				nvidia,e-lpbk = <TEGRA_PIN_DISABLE>;
			};

			spi8_miso_pag0 {
				nvidia,pins = "spi8_miso_pag0";
				nvidia,function = "rsvd1";
				nvidia,pull = <TEGRA_PIN_PULL_DOWN>;
				nvidia,tristate = <TEGRA_PIN_ENABLE>;
				nvidia,enable-input = <TEGRA_PIN_DISABLE>;
				nvidia,drv-type = <TEGRA_PIN_1X_DRIVER>;
				nvidia,e-io-od = <TEGRA_PIN_DISABLE>;
				nvidia,e-lpbk = <TEGRA_PIN_DISABLE>;
			};

			spi8_mosi_pag1 {
				nvidia,pins = "spi8_mosi_pag1";
				nvidia,function = "rsvd1";
				nvidia,pull = <TEGRA_PIN_PULL_DOWN>;
				nvidia,tristate = <TEGRA_PIN_ENABLE>;
				nvidia,enable-input = <TEGRA_PIN_DISABLE>;
				nvidia,drv-type = <TEGRA_PIN_1X_DRIVER>;
				nvidia,e-io-od = <TEGRA_PIN_DISABLE>;
				nvidia,e-lpbk = <TEGRA_PIN_DISABLE>;
			};

			spi8_cs0_n_pag2 {
				nvidia,pins = "spi8_cs0_n_pag2";
				nvidia,function = "rsvd1";
				nvidia,pull = <TEGRA_PIN_PULL_DOWN>;
				nvidia,tristate = <TEGRA_PIN_ENABLE>;
				nvidia,enable-input = <TEGRA_PIN_DISABLE>;
				nvidia,drv-type = <TEGRA_PIN_1X_DRIVER>;
				nvidia,e-io-od = <TEGRA_PIN_DISABLE>;
				nvidia,e-lpbk = <TEGRA_PIN_DISABLE>;
			};

			gen13_i2c_scl_pag3 {
				nvidia,pins = "gen13_i2c_scl_pag3";
				nvidia,function = "rsvd1";
				nvidia,pull = <TEGRA_PIN_PULL_DOWN>;
				nvidia,tristate = <TEGRA_PIN_ENABLE>;
				nvidia,enable-input = <TEGRA_PIN_DISABLE>;
				nvidia,drv-type = <TEGRA_PIN_1X_DRIVER>;
				nvidia,e-io-od = <TEGRA_PIN_DISABLE>;
				nvidia,e-lpbk = <TEGRA_PIN_DISABLE>;
			};

			gen13_i2c_sda_pag4 {
				nvidia,pins = "gen13_i2c_sda_pag4";
				nvidia,function = "rsvd1";
				nvidia,pull = <TEGRA_PIN_PULL_DOWN>;
				nvidia,tristate = <TEGRA_PIN_ENABLE>;
				nvidia,enable-input = <TEGRA_PIN_DISABLE>;
				nvidia,drv-type = <TEGRA_PIN_1X_DRIVER>;
				nvidia,e-io-od = <TEGRA_PIN_DISABLE>;
				nvidia,e-lpbk = <TEGRA_PIN_DISABLE>;
			};

			soc_gpio233_pag5 {
				nvidia,pins = "soc_gpio233_pag5";
				nvidia,function = "rsvd0";
				nvidia,pull = <TEGRA_PIN_PULL_DOWN>;
				nvidia,tristate = <TEGRA_PIN_ENABLE>;
				nvidia,enable-input = <TEGRA_PIN_DISABLE>;
				nvidia,drv-type = <TEGRA_PIN_1X_DRIVER>;
				nvidia,e-io-od = <TEGRA_PIN_DISABLE>;
				nvidia,e-lpbk = <TEGRA_PIN_DISABLE>;
			};

			soc_gpio234_pag6 {
				nvidia,pins = "soc_gpio234_pag6";
				nvidia,function = "rsvd0";
				nvidia,pull = <TEGRA_PIN_PULL_DOWN>;
				nvidia,tristate = <TEGRA_PIN_ENABLE>;
				nvidia,enable-input = <TEGRA_PIN_DISABLE>;
				nvidia,drv-type = <TEGRA_PIN_1X_DRIVER>;
				nvidia,e-io-od = <TEGRA_PIN_DISABLE>;
				nvidia,e-lpbk = <TEGRA_PIN_DISABLE>;
			};

			soc_gpio249_pag7 {
				nvidia,pins = "soc_gpio249_pag7";
				nvidia,function = "rsvd0";
				nvidia,pull = <TEGRA_PIN_PULL_DOWN>;
				nvidia,tristate = <TEGRA_PIN_ENABLE>;
				nvidia,enable-input = <TEGRA_PIN_DISABLE>;
				nvidia,drv-type = <TEGRA_PIN_1X_DRIVER>;
				nvidia,e-io-od = <TEGRA_PIN_DISABLE>;
				nvidia,e-lpbk = <TEGRA_PIN_DISABLE>;
			};

			soc_gpio235_pah0 {
				nvidia,pins = "soc_gpio235_pah0";
				nvidia,function = "rsvd0";
				nvidia,pull = <TEGRA_PIN_PULL_DOWN>;
				nvidia,tristate = <TEGRA_PIN_ENABLE>;
				nvidia,enable-input = <TEGRA_PIN_DISABLE>;
				nvidia,drv-type = <TEGRA_PIN_1X_DRIVER>;
				nvidia,e-io-od = <TEGRA_PIN_DISABLE>;
				nvidia,e-lpbk = <TEGRA_PIN_DISABLE>;
			};

			soc_gpio236_pah1 {
				nvidia,pins = "soc_gpio236_pah1";
				nvidia,function = "rsvd0";
				nvidia,pull = <TEGRA_PIN_PULL_DOWN>;
				nvidia,tristate = <TEGRA_PIN_ENABLE>;
				nvidia,enable-input = <TEGRA_PIN_DISABLE>;
				nvidia,drv-type = <TEGRA_PIN_1X_DRIVER>;
				nvidia,e-io-od = <TEGRA_PIN_DISABLE>;
				nvidia,e-lpbk = <TEGRA_PIN_DISABLE>;
			};

			soc_gpio237_pah2 {
				nvidia,pins = "soc_gpio237_pah2";
				nvidia,function = "rsvd0";
				nvidia,pull = <TEGRA_PIN_PULL_DOWN>;
				nvidia,tristate = <TEGRA_PIN_ENABLE>;
				nvidia,enable-input = <TEGRA_PIN_DISABLE>;
				nvidia,drv-type = <TEGRA_PIN_1X_DRIVER>;
				nvidia,e-io-od = <TEGRA_PIN_DISABLE>;
				nvidia,e-lpbk = <TEGRA_PIN_DISABLE>;
			};

			soc_gpio238_pah3 {
				nvidia,pins = "soc_gpio238_pah3";
				nvidia,function = "rsvd0";
				nvidia,pull = <TEGRA_PIN_PULL_DOWN>;
				nvidia,tristate = <TEGRA_PIN_ENABLE>;
				nvidia,enable-input = <TEGRA_PIN_DISABLE>;
				nvidia,drv-type = <TEGRA_PIN_1X_DRIVER>;
				nvidia,e-io-od = <TEGRA_PIN_DISABLE>;
				nvidia,e-lpbk = <TEGRA_PIN_DISABLE>;
			};

			spi9_sck_pah4 {
				nvidia,pins = "spi9_sck_pah4";
				nvidia,function = "rsvd1";
				nvidia,pull = <TEGRA_PIN_PULL_DOWN>;
				nvidia,tristate = <TEGRA_PIN_ENABLE>;
				nvidia,enable-input = <TEGRA_PIN_DISABLE>;
				nvidia,drv-type = <TEGRA_PIN_1X_DRIVER>;
				nvidia,e-io-od = <TEGRA_PIN_DISABLE>;
				nvidia,e-lpbk = <TEGRA_PIN_DISABLE>;
			};

			spi9_miso_pah5 {
				nvidia,pins = "spi9_miso_pah5";
				nvidia,function = "rsvd1";
				nvidia,pull = <TEGRA_PIN_PULL_DOWN>;
				nvidia,tristate = <TEGRA_PIN_ENABLE>;
				nvidia,enable-input = <TEGRA_PIN_DISABLE>;
				nvidia,drv-type = <TEGRA_PIN_1X_DRIVER>;
				nvidia,e-io-od = <TEGRA_PIN_DISABLE>;
				nvidia,e-lpbk = <TEGRA_PIN_DISABLE>;
			};

			spi9_mosi_pah6 {
				nvidia,pins = "spi9_mosi_pah6";
				nvidia,function = "rsvd1";
				nvidia,pull = <TEGRA_PIN_PULL_DOWN>;
				nvidia,tristate = <TEGRA_PIN_ENABLE>;
				nvidia,enable-input = <TEGRA_PIN_DISABLE>;
				nvidia,drv-type = <TEGRA_PIN_1X_DRIVER>;
				nvidia,e-io-od = <TEGRA_PIN_DISABLE>;
				nvidia,e-lpbk = <TEGRA_PIN_DISABLE>;
			};

			spi9_cs0_n_pah7 {
				nvidia,pins = "spi9_cs0_n_pah7";
				nvidia,function = "rsvd1";
				nvidia,pull = <TEGRA_PIN_PULL_DOWN>;
				nvidia,tristate = <TEGRA_PIN_ENABLE>;
				nvidia,enable-input = <TEGRA_PIN_DISABLE>;
				nvidia,drv-type = <TEGRA_PIN_1X_DRIVER>;
				nvidia,e-io-od = <TEGRA_PIN_DISABLE>;
				nvidia,e-lpbk = <TEGRA_PIN_DISABLE>;
			};

			spi9_cs1_n_paj0 {
				nvidia,pins = "spi9_cs1_n_paj0";
				nvidia,function = "rsvd1";
				nvidia,pull = <TEGRA_PIN_PULL_DOWN>;
				nvidia,tristate = <TEGRA_PIN_ENABLE>;
				nvidia,enable-input = <TEGRA_PIN_DISABLE>;
				nvidia,drv-type = <TEGRA_PIN_1X_DRIVER>;
				nvidia,e-io-od = <TEGRA_PIN_DISABLE>;
				nvidia,e-lpbk = <TEGRA_PIN_DISABLE>;
			};

			spi9_cs2_n_paj1 {
				nvidia,pins = "spi9_cs2_n_paj1";
				nvidia,function = "rsvd1";
				nvidia,pull = <TEGRA_PIN_PULL_DOWN>;
				nvidia,tristate = <TEGRA_PIN_ENABLE>;
				nvidia,enable-input = <TEGRA_PIN_DISABLE>;
				nvidia,drv-type = <TEGRA_PIN_1X_DRIVER>;
				nvidia,e-io-od = <TEGRA_PIN_DISABLE>;
				nvidia,e-lpbk = <TEGRA_PIN_DISABLE>;
			};

			sgmii1_sma_mdio_paj2 {
				nvidia,pins = "sgmii1_sma_mdio_paj2";
				nvidia,function = "rsvd2";
				nvidia,pull = <TEGRA_PIN_PULL_DOWN>;
				nvidia,tristate = <TEGRA_PIN_ENABLE>;
				nvidia,enable-input = <TEGRA_PIN_DISABLE>;
				nvidia,drv-type = <TEGRA_PIN_1X_DRIVER>;
				nvidia,e-io-od = <TEGRA_PIN_DISABLE>;
				nvidia,e-lpbk = <TEGRA_PIN_DISABLE>;
			};

			sgmii1_sma_mdc_paj3 {
				nvidia,pins = "sgmii1_sma_mdc_paj3";
				nvidia,function = "rsvd2";
				nvidia,pull = <TEGRA_PIN_PULL_DOWN>;
				nvidia,tristate = <TEGRA_PIN_ENABLE>;
				nvidia,enable-input = <TEGRA_PIN_DISABLE>;
				nvidia,drv-type = <TEGRA_PIN_1X_DRIVER>;
				nvidia,e-io-od = <TEGRA_PIN_DISABLE>;
				nvidia,e-lpbk = <TEGRA_PIN_DISABLE>;
			};

			uerror_paj4 {
				nvidia,pins = "uerror_paj4";
				nvidia,function = "rsvd1";
				nvidia,pull = <TEGRA_PIN_PULL_DOWN>;
				nvidia,tristate = <TEGRA_PIN_ENABLE>;
				nvidia,enable-input = <TEGRA_PIN_DISABLE>;
				nvidia,drv-type = <TEGRA_PIN_1X_DRIVER>;
				nvidia,e-io-od = <TEGRA_PIN_DISABLE>;
				nvidia,e-lpbk = <TEGRA_PIN_DISABLE>;
			};

			cerror_paj5 {
				nvidia,pins = "cerror_paj5";
				nvidia,function = "rsvd1";
				nvidia,pull = <TEGRA_PIN_PULL_DOWN>;
				nvidia,tristate = <TEGRA_PIN_ENABLE>;
				nvidia,enable-input = <TEGRA_PIN_DISABLE>;
				nvidia,drv-type = <TEGRA_PIN_1X_DRIVER>;
				nvidia,e-io-od = <TEGRA_PIN_DISABLE>;
				nvidia,e-lpbk = <TEGRA_PIN_DISABLE>;
			};

			soc_gpio290_paj6 {
				nvidia,pins = "soc_gpio290_paj6";
				nvidia,function = "rsvd1";
				nvidia,pull = <TEGRA_PIN_PULL_DOWN>;
				nvidia,tristate = <TEGRA_PIN_ENABLE>;
				nvidia,enable-input = <TEGRA_PIN_DISABLE>;
				nvidia,drv-type = <TEGRA_PIN_1X_DRIVER>;
				nvidia,e-io-od = <TEGRA_PIN_DISABLE>;
				nvidia,e-lpbk = <TEGRA_PIN_DISABLE>;
			};

			can2_stb_pad2 {
				nvidia,pins = "can2_stb_pad2";
				nvidia,function = "rsvd0";
				nvidia,pull = <TEGRA_PIN_PULL_DOWN>;
				nvidia,tristate = <TEGRA_PIN_ENABLE>;
				nvidia,enable-input = <TEGRA_PIN_DISABLE>;
				nvidia,drv-type = <TEGRA_PIN_DEFAULT_DRIVE_1X>;
				nvidia,e-lpbk = <TEGRA_PIN_DISABLE>;
			};

			can2_en_pad3 {
				nvidia,pins = "can2_en_pad3";
				nvidia,function = "rsvd0";
				nvidia,pull = <TEGRA_PIN_PULL_DOWN>;
				nvidia,tristate = <TEGRA_PIN_ENABLE>;
				nvidia,enable-input = <TEGRA_PIN_DISABLE>;
				nvidia,drv-type = <TEGRA_PIN_DEFAULT_DRIVE_1X>;
				nvidia,e-lpbk = <TEGRA_PIN_DISABLE>;
			};

			can2_err_pad4 {
				nvidia,pins = "can2_err_pad4";
				nvidia,function = "rsvd0";
				nvidia,pull = <TEGRA_PIN_PULL_DOWN>;
				nvidia,tristate = <TEGRA_PIN_ENABLE>;
				nvidia,enable-input = <TEGRA_PIN_DISABLE>;
				nvidia,drv-type = <TEGRA_PIN_DEFAULT_DRIVE_1X>;
				nvidia,e-lpbk = <TEGRA_PIN_DISABLE>;
			};

			can3_stb_pae2 {
				nvidia,pins = "can3_stb_pae2";
				nvidia,function = "rsvd0";
				nvidia,pull = <TEGRA_PIN_PULL_DOWN>;
				nvidia,tristate = <TEGRA_PIN_ENABLE>;
				nvidia,enable-input = <TEGRA_PIN_DISABLE>;
				nvidia,drv-type = <TEGRA_PIN_DEFAULT_DRIVE_1X>;
				nvidia,e-lpbk = <TEGRA_PIN_DISABLE>;
			};

			can3_en_pae3 {
				nvidia,pins = "can3_en_pae3";
				nvidia,function = "rsvd0";
				nvidia,pull = <TEGRA_PIN_PULL_DOWN>;
				nvidia,tristate = <TEGRA_PIN_ENABLE>;
				nvidia,enable-input = <TEGRA_PIN_DISABLE>;
				nvidia,drv-type = <TEGRA_PIN_DEFAULT_DRIVE_1X>;
				nvidia,e-lpbk = <TEGRA_PIN_DISABLE>;
			};

			can3_err_pae4 {
				nvidia,pins = "can3_err_pae4";
				nvidia,function = "rsvd0";
				nvidia,pull = <TEGRA_PIN_PULL_DOWN>;
				nvidia,tristate = <TEGRA_PIN_ENABLE>;
				nvidia,enable-input = <TEGRA_PIN_DISABLE>;
				nvidia,drv-type = <TEGRA_PIN_DEFAULT_DRIVE_1X>;
				nvidia,e-lpbk = <TEGRA_PIN_DISABLE>;
			};

			spi3_cs3_pj2 {
				nvidia,pins = "spi3_cs3_pj2";
				nvidia,function = "rsvd1";
				nvidia,pull = <TEGRA_PIN_PULL_DOWN>;
				nvidia,tristate = <TEGRA_PIN_ENABLE>;
				nvidia,enable-input = <TEGRA_PIN_DISABLE>;
				nvidia,drv-type = <TEGRA_PIN_1X_DRIVER>;
				nvidia,e-io-od = <TEGRA_PIN_DISABLE>;
				nvidia,e-lpbk = <TEGRA_PIN_DISABLE>;
			};

			spi1_sck_pj7 {
				nvidia,pins = "spi1_sck_pj7";
				nvidia,function = "rsvd1";
				nvidia,pull = <TEGRA_PIN_PULL_DOWN>;
				nvidia,tristate = <TEGRA_PIN_ENABLE>;
				nvidia,enable-input = <TEGRA_PIN_DISABLE>;
				nvidia,drv-type = <TEGRA_PIN_1X_DRIVER>;
				nvidia,e-io-od = <TEGRA_PIN_DISABLE>;
				nvidia,e-lpbk = <TEGRA_PIN_DISABLE>;
			};

			spi1_miso_pk0 {
				nvidia,pins = "spi1_miso_pk0";
				nvidia,function = "rsvd1";
				nvidia,pull = <TEGRA_PIN_PULL_DOWN>;
				nvidia,tristate = <TEGRA_PIN_ENABLE>;
				nvidia,enable-input = <TEGRA_PIN_DISABLE>;
				nvidia,drv-type = <TEGRA_PIN_1X_DRIVER>;
				nvidia,e-io-od = <TEGRA_PIN_DISABLE>;
				nvidia,e-lpbk = <TEGRA_PIN_DISABLE>;
			};

			spi1_mosi_pk1 {
				nvidia,pins = "spi1_mosi_pk1";
				nvidia,function = "rsvd1";
				nvidia,pull = <TEGRA_PIN_PULL_DOWN>;
				nvidia,tristate = <TEGRA_PIN_ENABLE>;
				nvidia,enable-input = <TEGRA_PIN_DISABLE>;
				nvidia,drv-type = <TEGRA_PIN_1X_DRIVER>;
				nvidia,e-io-od = <TEGRA_PIN_DISABLE>;
				nvidia,e-lpbk = <TEGRA_PIN_DISABLE>;
			};

			spi1_cs0_pk2 {
				nvidia,pins = "spi1_cs0_pk2";
				nvidia,function = "rsvd1";
				nvidia,pull = <TEGRA_PIN_PULL_DOWN>;
				nvidia,tristate = <TEGRA_PIN_ENABLE>;
				nvidia,enable-input = <TEGRA_PIN_DISABLE>;
				nvidia,drv-type = <TEGRA_PIN_1X_DRIVER>;
				nvidia,e-io-od = <TEGRA_PIN_DISABLE>;
				nvidia,e-lpbk = <TEGRA_PIN_DISABLE>;
			};

			spi1_cs1_pk3 {
				nvidia,pins = "spi1_cs1_pk3";
				nvidia,function = "rsvd1";
				nvidia,pull = <TEGRA_PIN_PULL_DOWN>;
				nvidia,tristate = <TEGRA_PIN_ENABLE>;
				nvidia,enable-input = <TEGRA_PIN_DISABLE>;
				nvidia,drv-type = <TEGRA_PIN_1X_DRIVER>;
				nvidia,e-io-od = <TEGRA_PIN_DISABLE>;
				nvidia,e-lpbk = <TEGRA_PIN_DISABLE>;
			};

			soc_gpio125_pl1 {
				nvidia,pins = "soc_gpio125_pl1";
				nvidia,function = "rsvd0";
				nvidia,pull = <TEGRA_PIN_PULL_DOWN>;
				nvidia,tristate = <TEGRA_PIN_ENABLE>;
				nvidia,enable-input = <TEGRA_PIN_DISABLE>;
				nvidia,drv-type = <TEGRA_PIN_1X_DRIVER>;
				nvidia,e-io-od = <TEGRA_PIN_DISABLE>;
				nvidia,e-lpbk = <TEGRA_PIN_DISABLE>;
			};

			soc_gpio128_pl4 {
				nvidia,pins = "soc_gpio128_pl4";
				nvidia,function = "rsvd0";
				nvidia,pull = <TEGRA_PIN_PULL_DOWN>;
				nvidia,tristate = <TEGRA_PIN_ENABLE>;
				nvidia,enable-input = <TEGRA_PIN_DISABLE>;
				nvidia,drv-type = <TEGRA_PIN_1X_DRIVER>;
				nvidia,e-io-od = <TEGRA_PIN_DISABLE>;
				nvidia,e-lpbk = <TEGRA_PIN_DISABLE>;
			};

			soc_gpio131_pl7 {
				nvidia,pins = "soc_gpio131_pl7";
				nvidia,function = "rsvd0";
				nvidia,pull = <TEGRA_PIN_PULL_DOWN>;
				nvidia,tristate = <TEGRA_PIN_ENABLE>;
				nvidia,enable-input = <TEGRA_PIN_DISABLE>;
				nvidia,drv-type = <TEGRA_PIN_1X_DRIVER>;
				nvidia,e-io-od = <TEGRA_PIN_DISABLE>;
				nvidia,e-lpbk = <TEGRA_PIN_DISABLE>;
			};

			gp_pwm9_pm0 {
				nvidia,pins = "gp_pwm9_pm0";
				nvidia,function = "rsvd1";
				nvidia,pull = <TEGRA_PIN_PULL_DOWN>;
				nvidia,tristate = <TEGRA_PIN_ENABLE>;
				nvidia,enable-input = <TEGRA_PIN_DISABLE>;
				nvidia,drv-type = <TEGRA_PIN_1X_DRIVER>;
				nvidia,e-io-od = <TEGRA_PIN_DISABLE>;
				nvidia,e-lpbk = <TEGRA_PIN_DISABLE>;
			};

			soc_gpio133_pm1 {
				nvidia,pins = "soc_gpio133_pm1";
				nvidia,function = "rsvd0";
				nvidia,pull = <TEGRA_PIN_PULL_DOWN>;
				nvidia,tristate = <TEGRA_PIN_ENABLE>;
				nvidia,enable-input = <TEGRA_PIN_DISABLE>;
				nvidia,drv-type = <TEGRA_PIN_1X_DRIVER>;
				nvidia,e-io-od = <TEGRA_PIN_DISABLE>;
				nvidia,e-lpbk = <TEGRA_PIN_DISABLE>;
			};

			soc_gpio138_pp0 {
				nvidia,pins = "soc_gpio138_pp0";
				nvidia,function = "rsvd0";
				nvidia,pull = <TEGRA_PIN_PULL_DOWN>;
				nvidia,tristate = <TEGRA_PIN_ENABLE>;
				nvidia,enable-input = <TEGRA_PIN_DISABLE>;
				nvidia,drv-type = <TEGRA_PIN_1X_DRIVER>;
				nvidia,e-io-od = <TEGRA_PIN_DISABLE>;
				nvidia,e-lpbk = <TEGRA_PIN_DISABLE>;
			};

			dap6_sclk_pp2 {
				nvidia,pins = "dap6_sclk_pp2";
				nvidia,function = "rsvd1";
				nvidia,pull = <TEGRA_PIN_PULL_DOWN>;
				nvidia,tristate = <TEGRA_PIN_ENABLE>;
				nvidia,enable-input = <TEGRA_PIN_DISABLE>;
				nvidia,drv-type = <TEGRA_PIN_1X_DRIVER>;
				nvidia,e-io-od = <TEGRA_PIN_DISABLE>;
				nvidia,e-lpbk = <TEGRA_PIN_DISABLE>;
			};

			dap6_dout_pp3 {
				nvidia,pins = "dap6_dout_pp3";
				nvidia,function = "rsvd1";
				nvidia,pull = <TEGRA_PIN_PULL_DOWN>;
				nvidia,tristate = <TEGRA_PIN_ENABLE>;
				nvidia,enable-input = <TEGRA_PIN_DISABLE>;
				nvidia,drv-type = <TEGRA_PIN_1X_DRIVER>;
				nvidia,e-io-od = <TEGRA_PIN_DISABLE>;
				nvidia,e-lpbk = <TEGRA_PIN_DISABLE>;
			};

			dap6_din_pp4 {
				nvidia,pins = "dap6_din_pp4";
				nvidia,function = "rsvd1";
				nvidia,pull = <TEGRA_PIN_PULL_DOWN>;
				nvidia,tristate = <TEGRA_PIN_ENABLE>;
				nvidia,enable-input = <TEGRA_PIN_DISABLE>;
				nvidia,drv-type = <TEGRA_PIN_1X_DRIVER>;
				nvidia,e-io-od = <TEGRA_PIN_DISABLE>;
				nvidia,e-lpbk = <TEGRA_PIN_DISABLE>;
			};

			dap6_fs_pp5 {
				nvidia,pins = "dap6_fs_pp5";
				nvidia,function = "rsvd1";
				nvidia,pull = <TEGRA_PIN_PULL_DOWN>;
				nvidia,tristate = <TEGRA_PIN_ENABLE>;
				nvidia,enable-input = <TEGRA_PIN_DISABLE>;
				nvidia,drv-type = <TEGRA_PIN_1X_DRIVER>;
				nvidia,e-io-od = <TEGRA_PIN_DISABLE>;
				nvidia,e-lpbk = <TEGRA_PIN_DISABLE>;
			};

			spi5_miso_pq3 {
				nvidia,pins = "spi5_miso_pq3";
				nvidia,function = "rsvd1";
				nvidia,pull = <TEGRA_PIN_PULL_DOWN>;
				nvidia,tristate = <TEGRA_PIN_ENABLE>;
				nvidia,enable-input = <TEGRA_PIN_DISABLE>;
				nvidia,drv-type = <TEGRA_PIN_1X_DRIVER>;
				nvidia,e-io-od = <TEGRA_PIN_DISABLE>;
				nvidia,e-lpbk = <TEGRA_PIN_DISABLE>;
			};

			spi5_cs0_pq5 {
				nvidia,pins = "spi5_cs0_pq5";
				nvidia,function = "rsvd1";
				nvidia,pull = <TEGRA_PIN_PULL_DOWN>;
				nvidia,tristate = <TEGRA_PIN_ENABLE>;
				nvidia,enable-input = <TEGRA_PIN_DISABLE>;
				nvidia,drv-type = <TEGRA_PIN_1X_DRIVER>;
				nvidia,e-io-od = <TEGRA_PIN_DISABLE>;
				nvidia,e-lpbk = <TEGRA_PIN_DISABLE>;
			};

			soc_gpio152_pq6 {
				nvidia,pins = "soc_gpio152_pq6";
				nvidia,function = "rsvd0";
				nvidia,pull = <TEGRA_PIN_PULL_DOWN>;
				nvidia,tristate = <TEGRA_PIN_ENABLE>;
				nvidia,enable-input = <TEGRA_PIN_DISABLE>;
				nvidia,drv-type = <TEGRA_PIN_1X_DRIVER>;
				nvidia,e-io-od = <TEGRA_PIN_DISABLE>;
				nvidia,e-lpbk = <TEGRA_PIN_DISABLE>;
			};

			gen11_i2c_scl_pr6 {
				nvidia,pins = "gen11_i2c_scl_pr6";
				nvidia,function = "rsvd1";
				nvidia,pull = <TEGRA_PIN_PULL_DOWN>;
				nvidia,tristate = <TEGRA_PIN_ENABLE>;
				nvidia,enable-input = <TEGRA_PIN_DISABLE>;
				nvidia,drv-type = <TEGRA_PIN_1X_DRIVER>;
				nvidia,e-io-od = <TEGRA_PIN_DISABLE>;
				nvidia,e-lpbk = <TEGRA_PIN_DISABLE>;
			};

			gen11_i2c_sda_pr7 {
				nvidia,pins = "gen11_i2c_sda_pr7";
				nvidia,function = "rsvd1";
				nvidia,pull = <TEGRA_PIN_PULL_DOWN>;
				nvidia,tristate = <TEGRA_PIN_ENABLE>;
				nvidia,enable-input = <TEGRA_PIN_DISABLE>;
				nvidia,drv-type = <TEGRA_PIN_1X_DRIVER>;
				nvidia,e-io-od = <TEGRA_PIN_DISABLE>;
				nvidia,e-lpbk = <TEGRA_PIN_DISABLE>;
			};

			soc_gpio171_pu1 {
				nvidia,pins = "soc_gpio171_pu1";
				nvidia,function = "rsvd0";
				nvidia,pull = <TEGRA_PIN_PULL_DOWN>;
				nvidia,tristate = <TEGRA_PIN_ENABLE>;
				nvidia,enable-input = <TEGRA_PIN_DISABLE>;
				nvidia,drv-type = <TEGRA_PIN_1X_DRIVER>;
				nvidia,e-io-od = <TEGRA_PIN_DISABLE>;
				nvidia,e-lpbk = <TEGRA_PIN_DISABLE>;
			};

			soc_gpio172_pu2 {
				nvidia,pins = "soc_gpio172_pu2";
				nvidia,function = "rsvd2";
				nvidia,pull = <TEGRA_PIN_PULL_DOWN>;
				nvidia,tristate = <TEGRA_PIN_ENABLE>;
				nvidia,enable-input = <TEGRA_PIN_DISABLE>;
				nvidia,drv-type = <TEGRA_PIN_1X_DRIVER>;
				nvidia,e-io-od = <TEGRA_PIN_DISABLE>;
				nvidia,e-lpbk = <TEGRA_PIN_DISABLE>;
			};

			soc_gpio175_pu5 {
				nvidia,pins = "soc_gpio175_pu5";
				nvidia,function = "rsvd0";
				nvidia,pull = <TEGRA_PIN_PULL_DOWN>;
				nvidia,tristate = <TEGRA_PIN_ENABLE>;
				nvidia,enable-input = <TEGRA_PIN_DISABLE>;
				nvidia,drv-type = <TEGRA_PIN_1X_DRIVER>;
				nvidia,e-io-od = <TEGRA_PIN_DISABLE>;
				nvidia,e-lpbk = <TEGRA_PIN_DISABLE>;
			};

			soc_gpio178_pv0 {
				nvidia,pins = "soc_gpio178_pv0";
				nvidia,function = "rsvd0";
				nvidia,pull = <TEGRA_PIN_PULL_DOWN>;
				nvidia,tristate = <TEGRA_PIN_ENABLE>;
				nvidia,enable-input = <TEGRA_PIN_DISABLE>;
				nvidia,drv-type = <TEGRA_PIN_1X_DRIVER>;
				nvidia,e-io-od = <TEGRA_PIN_DISABLE>;
				nvidia,e-lpbk = <TEGRA_PIN_DISABLE>;
			};

			uart4_tx_pv2 {
				nvidia,pins = "uart4_tx_pv2";
				nvidia,function = "rsvd1";
				nvidia,pull = <TEGRA_PIN_PULL_DOWN>;
				nvidia,tristate = <TEGRA_PIN_ENABLE>;
				nvidia,enable-input = <TEGRA_PIN_DISABLE>;
				nvidia,drv-type = <TEGRA_PIN_1X_DRIVER>;
				nvidia,e-io-od = <TEGRA_PIN_DISABLE>;
				nvidia,e-lpbk = <TEGRA_PIN_DISABLE>;
			};

			uart4_rx_pv3 {
				nvidia,pins = "uart4_rx_pv3";
				nvidia,function = "rsvd1";
				nvidia,pull = <TEGRA_PIN_PULL_DOWN>;
				nvidia,tristate = <TEGRA_PIN_ENABLE>;
				nvidia,enable-input = <TEGRA_PIN_DISABLE>;
				nvidia,drv-type = <TEGRA_PIN_1X_DRIVER>;
				nvidia,e-io-od = <TEGRA_PIN_DISABLE>;
				nvidia,e-lpbk = <TEGRA_PIN_DISABLE>;
			};

			uart4_rts_n_pv4 {
				nvidia,pins = "uart4_rts_n_pv4";
				nvidia,function = "rsvd1";
				nvidia,pull = <TEGRA_PIN_PULL_DOWN>;
				nvidia,tristate = <TEGRA_PIN_ENABLE>;
				nvidia,enable-input = <TEGRA_PIN_DISABLE>;
				nvidia,drv-type = <TEGRA_PIN_1X_DRIVER>;
				nvidia,e-io-od = <TEGRA_PIN_DISABLE>;
				nvidia,e-lpbk = <TEGRA_PIN_DISABLE>;
			};

			dap2_clk_pv6 {
				nvidia,pins = "dap2_clk_pv6";
				nvidia,function = "rsvd1";
				nvidia,pull = <TEGRA_PIN_PULL_DOWN>;
				nvidia,tristate = <TEGRA_PIN_ENABLE>;
				nvidia,enable-input = <TEGRA_PIN_DISABLE>;
				nvidia,drv-type = <TEGRA_PIN_1X_DRIVER>;
				nvidia,e-io-od = <TEGRA_PIN_DISABLE>;
				nvidia,e-lpbk = <TEGRA_PIN_DISABLE>;
			};

			dap2_dout_pv7 {
				nvidia,pins = "dap2_dout_pv7";
				nvidia,function = "rsvd1";
				nvidia,pull = <TEGRA_PIN_PULL_DOWN>;
				nvidia,tristate = <TEGRA_PIN_ENABLE>;
				nvidia,enable-input = <TEGRA_PIN_DISABLE>;
				nvidia,drv-type = <TEGRA_PIN_1X_DRIVER>;
				nvidia,e-io-od = <TEGRA_PIN_DISABLE>;
				nvidia,e-lpbk = <TEGRA_PIN_DISABLE>;
			};

			dap2_din_pw0 {
				nvidia,pins = "dap2_din_pw0";
				nvidia,function = "rsvd1";
				nvidia,pull = <TEGRA_PIN_PULL_DOWN>;
				nvidia,tristate = <TEGRA_PIN_ENABLE>;
				nvidia,enable-input = <TEGRA_PIN_DISABLE>;
				nvidia,drv-type = <TEGRA_PIN_1X_DRIVER>;
				nvidia,e-io-od = <TEGRA_PIN_DISABLE>;
				nvidia,e-lpbk = <TEGRA_PIN_DISABLE>;
			};

			dap2_fs_pw1 {
				nvidia,pins = "dap2_fs_pw1";
				nvidia,function = "rsvd1";
				nvidia,pull = <TEGRA_PIN_PULL_DOWN>;
				nvidia,tristate = <TEGRA_PIN_ENABLE>;
				nvidia,enable-input = <TEGRA_PIN_DISABLE>;
				nvidia,drv-type = <TEGRA_PIN_1X_DRIVER>;
				nvidia,e-io-od = <TEGRA_PIN_DISABLE>;
				nvidia,e-lpbk = <TEGRA_PIN_DISABLE>;
			};

			sdmmc1_clk_px0 {
				nvidia,pins = "sdmmc1_clk_px0";
				nvidia,function = "rsvd1";
				nvidia,pull = <TEGRA_PIN_PULL_DOWN>;
				nvidia,tristate = <TEGRA_PIN_ENABLE>;
				nvidia,enable-input = <TEGRA_PIN_DISABLE>;
				nvidia,drv-type = <TEGRA_PIN_DEFAULT_DRIVE_1X>;
				nvidia,e-lpbk = <TEGRA_PIN_DISABLE>;
			};

			sdmmc1_cmd_px1 {
				nvidia,pins = "sdmmc1_cmd_px1";
				nvidia,function = "rsvd1";
				nvidia,pull = <TEGRA_PIN_PULL_DOWN>;
				nvidia,tristate = <TEGRA_PIN_ENABLE>;
				nvidia,enable-input = <TEGRA_PIN_DISABLE>;
				nvidia,drv-type = <TEGRA_PIN_DEFAULT_DRIVE_1X>;
				nvidia,e-lpbk = <TEGRA_PIN_DISABLE>;
			};

			sdmmc1_dat0_px2 {
				nvidia,pins = "sdmmc1_dat0_px2";
				nvidia,function = "rsvd1";
				nvidia,pull = <TEGRA_PIN_PULL_DOWN>;
				nvidia,tristate = <TEGRA_PIN_ENABLE>;
				nvidia,enable-input = <TEGRA_PIN_DISABLE>;
				nvidia,drv-type = <TEGRA_PIN_DEFAULT_DRIVE_1X>;
				nvidia,e-lpbk = <TEGRA_PIN_DISABLE>;
			};

			sdmmc1_dat1_px3 {
				nvidia,pins = "sdmmc1_dat1_px3";
				nvidia,function = "rsvd1";
				nvidia,pull = <TEGRA_PIN_PULL_DOWN>;
				nvidia,tristate = <TEGRA_PIN_ENABLE>;
				nvidia,enable-input = <TEGRA_PIN_DISABLE>;
				nvidia,drv-type = <TEGRA_PIN_DEFAULT_DRIVE_1X>;
				nvidia,e-lpbk = <TEGRA_PIN_DISABLE>;
			};

			sdmmc1_dat2_px4 {
				nvidia,pins = "sdmmc1_dat2_px4";
				nvidia,function = "rsvd1";
				nvidia,pull = <TEGRA_PIN_PULL_DOWN>;
				nvidia,tristate = <TEGRA_PIN_ENABLE>;
				nvidia,enable-input = <TEGRA_PIN_DISABLE>;
				nvidia,drv-type = <TEGRA_PIN_DEFAULT_DRIVE_1X>;
				nvidia,e-lpbk = <TEGRA_PIN_DISABLE>;
			};

			sdmmc1_dat3_px5 {
				nvidia,pins = "sdmmc1_dat3_px5";
				nvidia,function = "rsvd1";
				nvidia,pull = <TEGRA_PIN_PULL_DOWN>;
				nvidia,tristate = <TEGRA_PIN_ENABLE>;
				nvidia,enable-input = <TEGRA_PIN_DISABLE>;
				nvidia,drv-type = <TEGRA_PIN_DEFAULT_DRIVE_1X>;
				nvidia,e-lpbk = <TEGRA_PIN_DISABLE>;
			};

			soc_gpio270_py0 {
				nvidia,pins = "soc_gpio270_py0";
				nvidia,function = "rsvd0";
				nvidia,pull = <TEGRA_PIN_PULL_DOWN>;
				nvidia,tristate = <TEGRA_PIN_ENABLE>;
				nvidia,enable-input = <TEGRA_PIN_DISABLE>;
				nvidia,drv-type = <TEGRA_PIN_1X_DRIVER>;
				nvidia,e-io-od = <TEGRA_PIN_DISABLE>;
				nvidia,e-lpbk = <TEGRA_PIN_DISABLE>;
			};

			soc_gpio272_py2 {
				nvidia,pins = "soc_gpio272_py2";
				nvidia,function = "rsvd0";
				nvidia,pull = <TEGRA_PIN_PULL_DOWN>;
				nvidia,tristate = <TEGRA_PIN_ENABLE>;
				nvidia,enable-input = <TEGRA_PIN_DISABLE>;
				nvidia,drv-type = <TEGRA_PIN_1X_DRIVER>;
				nvidia,e-io-od = <TEGRA_PIN_DISABLE>;
				nvidia,e-lpbk = <TEGRA_PIN_DISABLE>;
			};

			soc_gpio276_py6 {
				nvidia,pins = "soc_gpio276_py6";
				nvidia,function = "rsvd0";
				nvidia,pull = <TEGRA_PIN_PULL_DOWN>;
				nvidia,tristate = <TEGRA_PIN_ENABLE>;
				nvidia,enable-input = <TEGRA_PIN_DISABLE>;
				nvidia,drv-type = <TEGRA_PIN_1X_DRIVER>;
				nvidia,e-io-od = <TEGRA_PIN_DISABLE>;
				nvidia,e-lpbk = <TEGRA_PIN_DISABLE>;
			};

			soc_gpio277_py7 {
				nvidia,pins = "soc_gpio277_py7";
				nvidia,function = "rsvd0";
				nvidia,pull = <TEGRA_PIN_PULL_DOWN>;
				nvidia,tristate = <TEGRA_PIN_ENABLE>;
				nvidia,enable-input = <TEGRA_PIN_DISABLE>;
				nvidia,drv-type = <TEGRA_PIN_1X_DRIVER>;
				nvidia,e-io-od = <TEGRA_PIN_DISABLE>;
				nvidia,e-lpbk = <TEGRA_PIN_DISABLE>;
			};

			soc_gpio278_pz0 {
				nvidia,pins = "soc_gpio278_pz0";
				nvidia,function = "rsvd0";
				nvidia,pull = <TEGRA_PIN_PULL_DOWN>;
				nvidia,tristate = <TEGRA_PIN_ENABLE>;
				nvidia,enable-input = <TEGRA_PIN_DISABLE>;
				nvidia,drv-type = <TEGRA_PIN_1X_DRIVER>;
				nvidia,e-io-od = <TEGRA_PIN_DISABLE>;
				nvidia,e-lpbk = <TEGRA_PIN_DISABLE>;
			};

			xhalt_trig_pz2 {
				nvidia,pins = "xhalt_trig_pz2";
				nvidia,function = "rsvd1";
				nvidia,pull = <TEGRA_PIN_PULL_DOWN>;
				nvidia,tristate = <TEGRA_PIN_ENABLE>;
				nvidia,enable-input = <TEGRA_PIN_DISABLE>;
				nvidia,drv-type = <TEGRA_PIN_1X_DRIVER>;
				nvidia,e-io-od = <TEGRA_PIN_DISABLE>;
				nvidia,e-lpbk = <TEGRA_PIN_DISABLE>;
			};

			soc_gpio281_pz3 {
				nvidia,pins = "soc_gpio281_pz3";
				nvidia,function = "rsvd0";
				nvidia,pull = <TEGRA_PIN_PULL_DOWN>;
				nvidia,tristate = <TEGRA_PIN_ENABLE>;
				nvidia,enable-input = <TEGRA_PIN_DISABLE>;
				nvidia,drv-type = <TEGRA_PIN_1X_DRIVER>;
				nvidia,e-io-od = <TEGRA_PIN_DISABLE>;
				nvidia,e-lpbk = <TEGRA_PIN_DISABLE>;
			};

			soc_gpio282_pz4 {
				nvidia,pins = "soc_gpio282_pz4";
				nvidia,function = "rsvd0";
				nvidia,pull = <TEGRA_PIN_PULL_DOWN>;
				nvidia,tristate = <TEGRA_PIN_ENABLE>;
				nvidia,enable-input = <TEGRA_PIN_DISABLE>;
				nvidia,drv-type = <TEGRA_PIN_1X_DRIVER>;
				nvidia,e-io-od = <TEGRA_PIN_DISABLE>;
				nvidia,e-lpbk = <TEGRA_PIN_DISABLE>;
			};

			soc_gpio286_pal0 {
				nvidia,pins = "soc_gpio286_pal0";
				nvidia,function = "rsvd0";
				nvidia,pull = <TEGRA_PIN_PULL_DOWN>;
				nvidia,tristate = <TEGRA_PIN_ENABLE>;
				nvidia,enable-input = <TEGRA_PIN_DISABLE>;
				nvidia,drv-type = <TEGRA_PIN_1X_DRIVER>;
				nvidia,e-io-od = <TEGRA_PIN_DISABLE>;
				nvidia,e-lpbk = <TEGRA_PIN_DISABLE>;
			};

			soc_gpio288_pal2 {
				nvidia,pins = "soc_gpio288_pal2";
				nvidia,function = "rsvd0";
				nvidia,pull = <TEGRA_PIN_PULL_DOWN>;
				nvidia,tristate = <TEGRA_PIN_ENABLE>;
				nvidia,enable-input = <TEGRA_PIN_DISABLE>;
				nvidia,drv-type = <TEGRA_PIN_1X_DRIVER>;
				nvidia,e-io-od = <TEGRA_PIN_DISABLE>;
				nvidia,e-lpbk = <TEGRA_PIN_DISABLE>;
			};
		};

		drive {
		};
};

